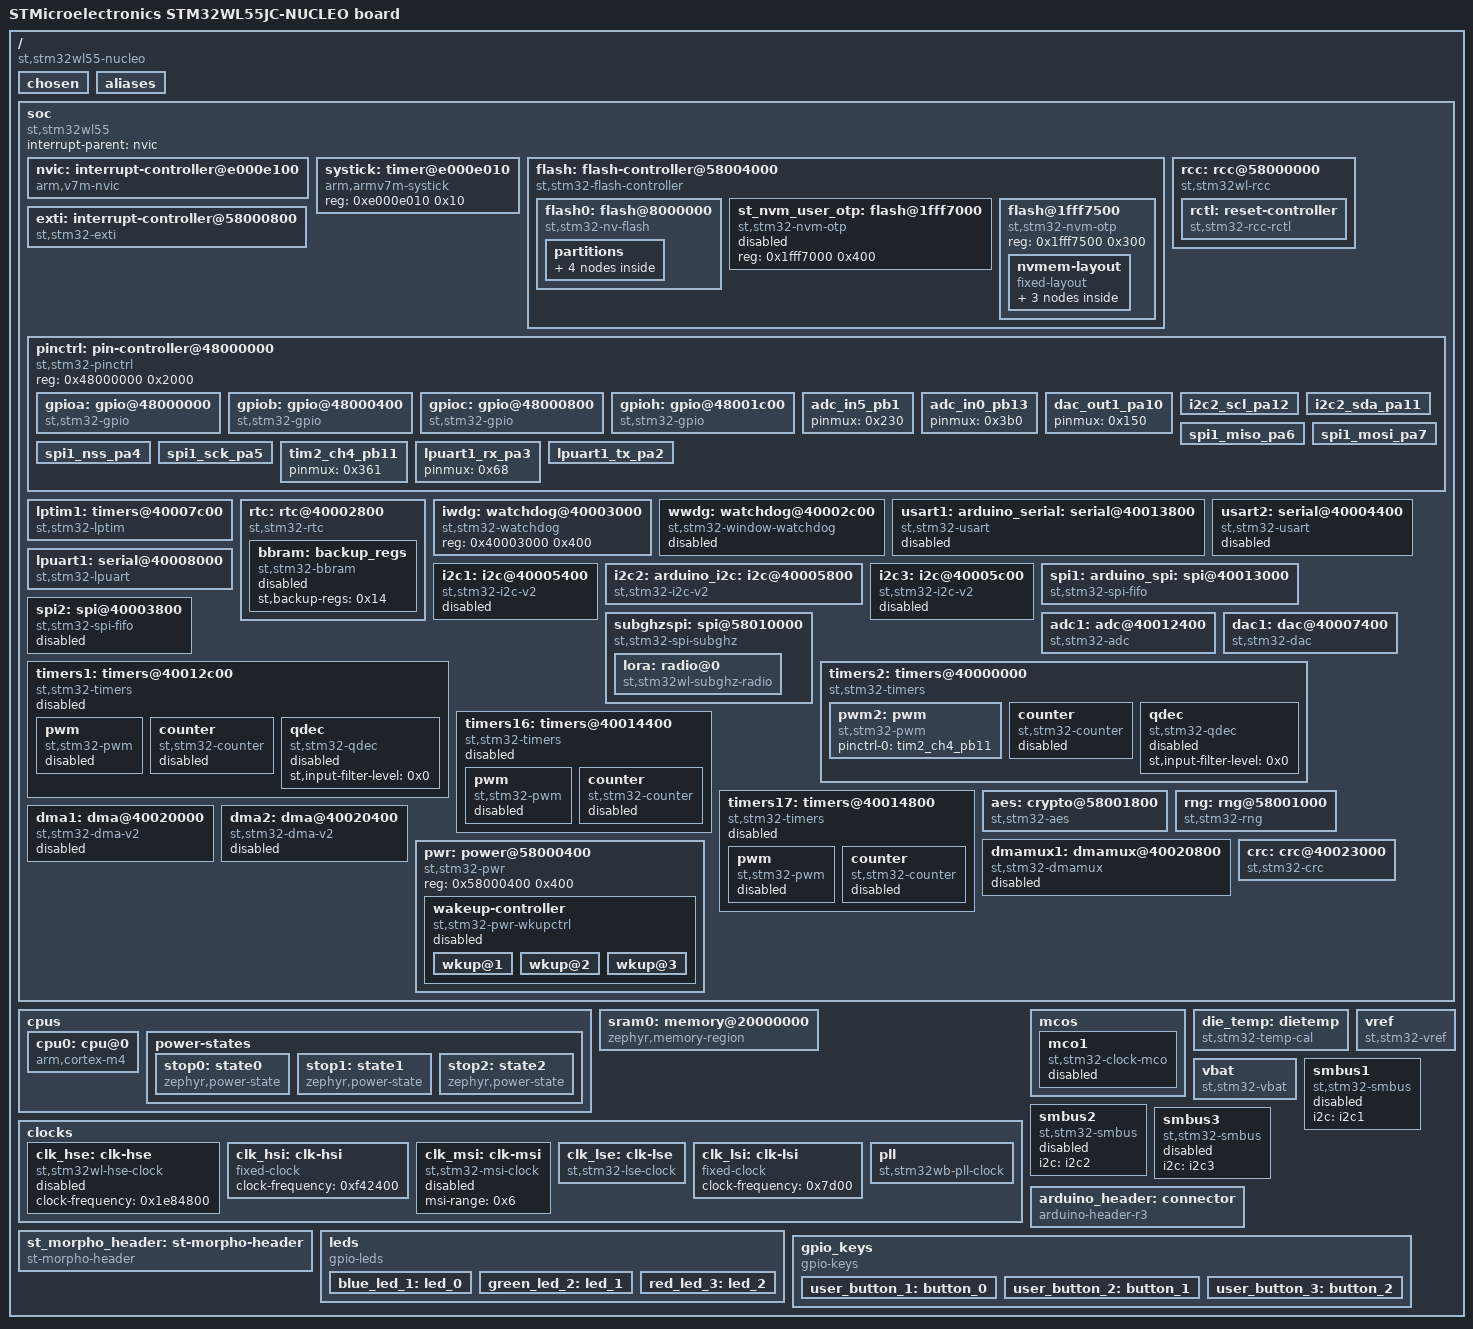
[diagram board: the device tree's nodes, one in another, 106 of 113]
/dts-v1/;

/* node '/' defined in zephyr\dts\common\skeleton.dtsi:9 */
/ {
	#address-cells = < 0x1 >;                              /* in zephyr\dts\common\skeleton.dtsi:10 */
	#size-cells = < 0x1 >;                                 /* in zephyr\dts\common\skeleton.dtsi:11 */
	model = "STMicroelectronics STM32WL55JC-NUCLEO board"; /* in zephyr\boards\st\nucleo_wl55jc\nucleo_wl55jc.dts:15 */
	compatible = "st,stm32wl55-nucleo";                    /* in zephyr\boards\st\nucleo_wl55jc\nucleo_wl55jc.dts:16 */

	/* node '/chosen' defined in zephyr\dts\common\skeleton.dtsi:13 */
	chosen {
		zephyr,crc = &crc;                        /* in zephyr\dts\arm\st\wl\stm32wl.dtsi:24 */
		zephyr,entropy = &rng;                    /* in zephyr\dts\arm\st\wl\stm32wl.dtsi:25 */
		zephyr,flash-controller = &flash;         /* in zephyr\dts\arm\st\wl\stm32wl.dtsi:26 */
		zephyr,console = &lpuart1;                /* in zephyr\boards\st\nucleo_wl55jc\nucleo_wl55jc.dts:19 */
		zephyr,shell-uart = &lpuart1;             /* in zephyr\boards\st\nucleo_wl55jc\nucleo_wl55jc.dts:20 */
		zephyr,sram = &sram0;                     /* in zephyr\boards\st\nucleo_wl55jc\nucleo_wl55jc.dts:21 */
		zephyr,flash = &flash0;                   /* in zephyr\boards\st\nucleo_wl55jc\nucleo_wl55jc.dts:22 */
		zephyr,code-partition = &slot0_partition; /* in zephyr\boards\st\nucleo_wl55jc\nucleo_wl55jc.dts:23 */
		zephyr,system-timer = &lptim1;            /* in zephyr\boards\st\nucleo_wl55jc\nucleo_wl55jc.dts:24 */
	};

	/* node '/aliases' defined in zephyr\dts\common\skeleton.dtsi:15 */
	aliases {
		rtc = &rtc;            /* in zephyr\boards\st\nucleo_wl55jc\nucleo_wl55jc.dts:70 */
		sw0 = &user_button_1;  /* in zephyr\boards\st\nucleo_wl55jc\nucleo_wl55jc.dts:71 */
		sw1 = &user_button_2;  /* in zephyr\boards\st\nucleo_wl55jc\nucleo_wl55jc.dts:72 */
		sw2 = &user_button_3;  /* in zephyr\boards\st\nucleo_wl55jc\nucleo_wl55jc.dts:73 */
		lora0 = &lora;         /* in zephyr\boards\st\nucleo_wl55jc\nucleo_wl55jc.dts:74 */
		watchdog0 = &iwdg;     /* in zephyr\boards\st\nucleo_wl55jc\nucleo_wl55jc.dts:75 */
		die-temp0 = &die_temp; /* in zephyr\boards\st\nucleo_wl55jc\nucleo_wl55jc.dts:76 */
		volt-sensor0 = &vref;  /* in zephyr\boards\st\nucleo_wl55jc\nucleo_wl55jc.dts:77 */
		volt-sensor1 = &vbat;  /* in zephyr\boards\st\nucleo_wl55jc\nucleo_wl55jc.dts:78 */
		led0 = &red_led_3;     /* in ..\brightnessm_iot\build\zephyr\boards\nucleo_wl55jc.overlay:7 */
	};

	/* node '/soc' defined in zephyr\dts\arm\armv7-m.dtsi:6 */
	soc {
		#address-cells = < 0x1 >;     /* in zephyr\dts\arm\armv7-m.dtsi:7 */
		#size-cells = < 0x1 >;        /* in zephyr\dts\arm\armv7-m.dtsi:8 */
		interrupt-parent = < &nvic >; /* in zephyr\dts\arm\armv7-m.dtsi:10 */
		ranges;                       /* in zephyr\dts\arm\armv7-m.dtsi:11 */
		compatible = "st,stm32wl55",
		             "st,stm32wl",
		             "simple-bus";    /* in zephyr\dts\arm\st\wl\stm32wl55.dtsi:11 */

		/* node '/soc/interrupt-controller@e000e100' defined in zephyr\dts\arm\armv7-m.dtsi:13 */
		nvic: interrupt-controller@e000e100 {
			#address-cells = < 0x1 >;            /* in zephyr\dts\arm\armv7-m.dtsi:14 */
			compatible = "arm,v7m-nvic";         /* in zephyr\dts\arm\armv7-m.dtsi:15 */
			reg = < 0xe000e100 0xc00 >;          /* in zephyr\dts\arm\armv7-m.dtsi:16 */
			interrupt-controller;                /* in zephyr\dts\arm\armv7-m.dtsi:17 */
			#interrupt-cells = < 0x2 >;          /* in zephyr\dts\arm\armv7-m.dtsi:18 */
			arm,num-irq-priority-bits = < 0x4 >; /* in zephyr\dts\arm\st\wl\stm32wl.dtsi:673 */
			phandle = < 0x1 >;                   /* in zephyr\dts\arm\armv7-m.dtsi:10 */
		};

		/* node '/soc/timer@e000e010' defined in zephyr\dts\arm\armv7-m.dtsi:21 */
		systick: timer@e000e010 {
			compatible = "arm,armv7m-systick"; /* in zephyr\dts\arm\armv7-m.dtsi:22 */
			reg = < 0xe000e010 0x10 >;         /* in zephyr\dts\arm\armv7-m.dtsi:23 */
		};

		/* node '/soc/flash-controller@58004000' defined in zephyr\dts\arm\st\wl\stm32wl.dtsi:123 */
		flash: flash-controller@58004000 {
			compatible = "st,stm32-flash-controller",
			             "st,stm32l4-flash-controller"; /* in zephyr\dts\arm\st\wl\stm32wl.dtsi:124 */
			reg = < 0x58004000 0x400 >;                 /* in zephyr\dts\arm\st\wl\stm32wl.dtsi:125 */
			interrupts = < 0x4 0x0 >;                   /* in zephyr\dts\arm\st\wl\stm32wl.dtsi:126 */
			#address-cells = < 0x1 >;                   /* in zephyr\dts\arm\st\wl\stm32wl.dtsi:128 */
			#size-cells = < 0x1 >;                      /* in zephyr\dts\arm\st\wl\stm32wl.dtsi:129 */
			ranges;                                     /* in zephyr\dts\arm\st\wl\stm32wl.dtsi:130 */

			/* node '/soc/flash-controller@58004000/flash@8000000' defined in zephyr\dts\arm\st\wl\stm32wl.dtsi:132 */
			flash0: flash@8000000 {
				compatible = "st,stm32-nv-flash",
				             "soc-nv-flash";        /* in zephyr\dts\arm\st\wl\stm32wl.dtsi:133 */
				#address-cells = < 0x1 >;           /* in zephyr\dts\arm\st\wl\stm32wl.dtsi:134 */
				#size-cells = < 0x1 >;              /* in zephyr\dts\arm\st\wl\stm32wl.dtsi:135 */
				write-block-size = < 0x8 >;         /* in zephyr\dts\arm\st\wl\stm32wl.dtsi:136 */
				erase-block-size = < 0x800 >;       /* in zephyr\dts\arm\st\wl\stm32wl.dtsi:137 */
				max-erase-time = < 0x19 >;          /* in zephyr\dts\arm\st\wl\stm32wl.dtsi:139 */
				reg = < 0x8000000 0x40000 >;        /* in zephyr\dts\arm\st\wl\stm32wl55Xc.dtsi:16 */
				ranges = < 0x0 0x8000000 0x40000 >; /* in zephyr\dts\arm\st\wl\stm32wl55Xc.dtsi:17 */

				/* node '/soc/flash-controller@58004000/flash@8000000/partitions' defined in zephyr\boards\st\nucleo_wl55jc\nucleo_wl55jc.dts:204 */
				partitions {
					#address-cells = < 0x1 >; /* in zephyr\boards\st\nucleo_wl55jc\nucleo_wl55jc.dts:205 */
					#size-cells = < 0x1 >;    /* in zephyr\boards\st\nucleo_wl55jc\nucleo_wl55jc.dts:206 */
					ranges;                   /* in zephyr\boards\st\nucleo_wl55jc\nucleo_wl55jc.dts:207 */

					/* node '/soc/flash-controller@58004000/flash@8000000/partitions/partition@0' defined in zephyr\boards\st\nucleo_wl55jc\nucleo_wl55jc.dts:209 */
					boot_partition: partition@0 {
						compatible = "zephyr,mapped-partition"; /* in zephyr\boards\st\nucleo_wl55jc\nucleo_wl55jc.dts:210 */
						label = "mcuboot";                      /* in zephyr\boards\st\nucleo_wl55jc\nucleo_wl55jc.dts:211 */
						reg = < 0x0 0xc000 >;                   /* in zephyr\boards\st\nucleo_wl55jc\nucleo_wl55jc.dts:212 */
						read-only;                              /* in zephyr\boards\st\nucleo_wl55jc\nucleo_wl55jc.dts:213 */
					};

					/* node '/soc/flash-controller@58004000/flash@8000000/partitions/partition@c000' defined in zephyr\boards\st\nucleo_wl55jc\nucleo_wl55jc.dts:216 */
					slot0_partition: partition@c000 {
						compatible = "zephyr,mapped-partition"; /* in zephyr\boards\st\nucleo_wl55jc\nucleo_wl55jc.dts:217 */
						label = "image-0";                      /* in zephyr\boards\st\nucleo_wl55jc\nucleo_wl55jc.dts:218 */
						reg = < 0xc000 0x18800 >;               /* in zephyr\boards\st\nucleo_wl55jc\nucleo_wl55jc.dts:219 */
					};

					/* node '/soc/flash-controller@58004000/flash@8000000/partitions/partition@24800' defined in zephyr\boards\st\nucleo_wl55jc\nucleo_wl55jc.dts:222 */
					slot1_partition: partition@24800 {
						compatible = "zephyr,mapped-partition"; /* in zephyr\boards\st\nucleo_wl55jc\nucleo_wl55jc.dts:223 */
						label = "image-1";                      /* in zephyr\boards\st\nucleo_wl55jc\nucleo_wl55jc.dts:224 */
						reg = < 0x24800 0x19000 >;              /* in zephyr\boards\st\nucleo_wl55jc\nucleo_wl55jc.dts:225 */
					};

					/* node '/soc/flash-controller@58004000/flash@8000000/partitions/partition@3d800' defined in zephyr\boards\st\nucleo_wl55jc\nucleo_wl55jc.dts:228 */
					storage_partition: partition@3d800 {
						compatible = "zephyr,mapped-partition"; /* in zephyr\boards\st\nucleo_wl55jc\nucleo_wl55jc.dts:229 */
						label = "storage";                      /* in zephyr\boards\st\nucleo_wl55jc\nucleo_wl55jc.dts:230 */
						reg = < 0x3d800 0x2800 >;               /* in zephyr\boards\st\nucleo_wl55jc\nucleo_wl55jc.dts:231 */
					};
				};
			};

			/* node '/soc/flash-controller@58004000/flash@1fff7000' defined in zephyr\dts\arm\st\wl\stm32wl.dtsi:142 */
			st_nvm_user_otp: flash@1fff7000 {
				compatible = "st,stm32-nvm-otp"; /* in zephyr\dts\arm\st\wl\stm32wl.dtsi:143 */
				reg = < 0x1fff7000 0x400 >;      /* in zephyr\dts\arm\st\wl\stm32wl.dtsi:144 */
				status = "disabled";             /* in zephyr\dts\arm\st\wl\stm32wl.dtsi:145 */
			};

			/* node '/soc/flash-controller@58004000/flash@1fff7500' defined in zephyr\dts\arm\st\wl\stm32wl.dtsi:149 */
			flash@1fff7500 {
				compatible = "st,stm32-nvm-otp"; /* in zephyr\dts\arm\st\wl\stm32wl.dtsi:150 */
				reg = < 0x1fff7500 0x300 >;      /* in zephyr\dts\arm\st\wl\stm32wl.dtsi:151 */

				/* node '/soc/flash-controller@58004000/flash@1fff7500/nvmem-layout' defined in zephyr\dts\arm\st\wl\stm32wl.dtsi:153 */
				nvmem-layout {
					compatible = "fixed-layout"; /* in zephyr\dts\arm\st\wl\stm32wl.dtsi:154 */
					#address-cells = < 0x1 >;    /* in zephyr\dts\arm\st\wl\stm32wl.dtsi:155 */
					#size-cells = < 0x1 >;       /* in zephyr\dts\arm\st\wl\stm32wl.dtsi:156 */

					/* node '/soc/flash-controller@58004000/flash@1fff7500/nvmem-layout/ts-cal1@a8' defined in zephyr\dts\arm\st\wl\stm32wl.dtsi:158 */
					ts_cal1_otp: ts-cal1@a8 {
						reg = < 0xa8 0x2 >;          /* in zephyr\dts\arm\st\wl\stm32wl.dtsi:159 */
						#nvmem-cell-cells = < 0x0 >; /* in zephyr\dts\arm\st\wl\stm32wl.dtsi:160 */
						read-only;                   /* in zephyr\dts\arm\st\wl\stm32wl.dtsi:161 */
						phandle = < 0x18 >;          /* in zephyr\dts\arm\st\wl\stm32wl.dtsi:623 */
					};

					/* node '/soc/flash-controller@58004000/flash@1fff7500/nvmem-layout/vrefint@aa' defined in zephyr\dts\arm\st\wl\stm32wl.dtsi:164 */
					vrefint_otp: vrefint@aa {
						reg = < 0xaa 0x2 >;          /* in zephyr\dts\arm\st\wl\stm32wl.dtsi:165 */
						#nvmem-cell-cells = < 0x0 >; /* in zephyr\dts\arm\st\wl\stm32wl.dtsi:166 */
						read-only;                   /* in zephyr\dts\arm\st\wl\stm32wl.dtsi:167 */
						phandle = < 0x1b >;          /* in zephyr\dts\arm\st\wl\stm32wl.dtsi:634 */
					};

					/* node '/soc/flash-controller@58004000/flash@1fff7500/nvmem-layout/ts-cal2@c8' defined in zephyr\dts\arm\st\wl\stm32wl.dtsi:170 */
					ts_cal2_otp: ts-cal2@c8 {
						reg = < 0xc8 0x2 >;          /* in zephyr\dts\arm\st\wl\stm32wl.dtsi:171 */
						#nvmem-cell-cells = < 0x0 >; /* in zephyr\dts\arm\st\wl\stm32wl.dtsi:172 */
						read-only;                   /* in zephyr\dts\arm\st\wl\stm32wl.dtsi:173 */
						phandle = < 0x19 >;          /* in zephyr\dts\arm\st\wl\stm32wl.dtsi:623 */
					};
				};
			};
		};

		/* node '/soc/rcc@58000000' defined in zephyr\dts\arm\st\wl\stm32wl.dtsi:179 */
		rcc: rcc@58000000 {
			compatible = "st,stm32wl-rcc";   /* in zephyr\dts\arm\st\wl\stm32wl.dtsi:180 */
			#clock-cells = < 0x2 >;          /* in zephyr\dts\arm\st\wl\stm32wl.dtsi:181 */
			reg = < 0x58000000 0x400 >;      /* in zephyr\dts\arm\st\wl\stm32wl.dtsi:182 */
			clocks = < &pll >;               /* in zephyr\boards\st\nucleo_wl55jc\nucleo_wl55jc.dts:111 */
			clock-frequency = < 0x2dc6c00 >; /* in zephyr\boards\st\nucleo_wl55jc\nucleo_wl55jc.dts:112 */
			cpu1-prescaler = < 0x1 >;        /* in zephyr\boards\st\nucleo_wl55jc\nucleo_wl55jc.dts:113 */
			cpu2-prescaler = < 0x1 >;        /* in zephyr\boards\st\nucleo_wl55jc\nucleo_wl55jc.dts:114 */
			ahb3-prescaler = < 0x1 >;        /* in zephyr\boards\st\nucleo_wl55jc\nucleo_wl55jc.dts:115 */
			apb1-prescaler = < 0x1 >;        /* in zephyr\boards\st\nucleo_wl55jc\nucleo_wl55jc.dts:116 */
			apb2-prescaler = < 0x1 >;        /* in zephyr\boards\st\nucleo_wl55jc\nucleo_wl55jc.dts:117 */
			phandle = < 0x3 >;               /* in zephyr\dts\arm\st\wl\stm32wl.dtsi:196 */

			/* node '/soc/rcc@58000000/reset-controller' defined in zephyr\dts\arm\st\wl\stm32wl.dtsi:184 */
			rctl: reset-controller {
				compatible = "st,stm32-rcc-rctl"; /* in zephyr\dts\arm\st\wl\stm32wl.dtsi:185 */
				#reset-cells = < 0x1 >;           /* in zephyr\dts\arm\st\wl\stm32wl.dtsi:186 */
				phandle = < 0x4 >;                /* in zephyr\dts\arm\st\wl\stm32wl.dtsi:249 */
			};
		};

		/* node '/soc/interrupt-controller@58000800' defined in zephyr\dts\arm\st\wl\stm32wl.dtsi:190 */
		exti: interrupt-controller@58000800 {
			compatible = "st,stm32-exti";  /* in zephyr\dts\arm\st\wl\stm32wl.dtsi:191 */
			interrupt-controller;          /* in zephyr\dts\arm\st\wl\stm32wl.dtsi:192 */
			#interrupt-cells = < 0x1 >;    /* in zephyr\dts\arm\st\wl\stm32wl.dtsi:193 */
			#address-cells = < 0x0 >;      /* in zephyr\dts\arm\st\wl\stm32wl.dtsi:194 */
			reg = < 0x58000800 0x400 >;    /* in zephyr\dts\arm\st\wl\stm32wl.dtsi:195 */
			clocks = < &rcc 0x54 0x100 >;  /* in zephyr\dts\arm\st\wl\stm32wl.dtsi:196 */
			num-lines = < 0x40 >;          /* in zephyr\dts\arm\st\wl\stm32wl.dtsi:197 */
			interrupts = < 0x6 0x0 >,
			             < 0x7 0x0 >,
			             < 0x8 0x0 >,
			             < 0x9 0x0 >,
			             < 0xa 0x0 >,
			             < 0x16 0x0 >,
			             < 0x29 0x0 >;     /* in zephyr\dts\arm\st\wl\stm32wl.dtsi:198 */
			interrupt-names = "line0",
			                  "line1",
			                  "line2",
			                  "line3",
			                  "line4",
			                  "line5-9",
			                  "line10-15"; /* in zephyr\dts\arm\st\wl\stm32wl.dtsi:200 */
			line-ranges = < 0x0 0x1 >,
			              < 0x1 0x1 >,
			              < 0x2 0x1 >,
			              < 0x3 0x1 >,
			              < 0x4 0x1 >,
			              < 0x5 0x5 >,
			              < 0xa 0x6 >;     /* in zephyr\dts\arm\st\wl\stm32wl.dtsi:202 */
		};

		/* node '/soc/pin-controller@48000000' defined in zephyr\dts\arm\st\wl\stm32wl.dtsi:206 */
		pinctrl: pin-controller@48000000 {
			compatible = "st,stm32-pinctrl"; /* in zephyr\dts\arm\st\wl\stm32wl.dtsi:207 */
			#address-cells = < 0x1 >;        /* in zephyr\dts\arm\st\wl\stm32wl.dtsi:208 */
			#size-cells = < 0x1 >;           /* in zephyr\dts\arm\st\wl\stm32wl.dtsi:209 */
			reg = < 0x48000000 0x2000 >;     /* in zephyr\dts\arm\st\wl\stm32wl.dtsi:210 */
			ranges;                          /* in zephyr\dts\arm\st\wl\stm32wl.dtsi:211 */

			/* node '/soc/pin-controller@48000000/gpio@48000000' defined in zephyr\dts\arm\st\wl\stm32wl.dtsi:213 */
			gpioa: gpio@48000000 {
				compatible = "st,stm32-gpio"; /* in zephyr\dts\arm\st\wl\stm32wl.dtsi:214 */
				gpio-controller;              /* in zephyr\dts\arm\st\wl\stm32wl.dtsi:215 */
				#gpio-cells = < 0x2 >;        /* in zephyr\dts\arm\st\wl\stm32wl.dtsi:216 */
				reg = < 0x48000000 0x400 >;   /* in zephyr\dts\arm\st\wl\stm32wl.dtsi:217 */
				clocks = < &rcc 0x4c 0x1 >;   /* in zephyr\dts\arm\st\wl\stm32wl.dtsi:218 */
				phandle = < 0x9 >;            /* in zephyr\boards\st\nucleo_wl55jc\nucleo_wl55jc.dts:130 */
			};

			/* node '/soc/pin-controller@48000000/gpio@48000400' defined in zephyr\dts\arm\st\wl\stm32wl.dtsi:221 */
			gpiob: gpio@48000400 {
				compatible = "st,stm32-gpio"; /* in zephyr\dts\arm\st\wl\stm32wl.dtsi:222 */
				gpio-controller;              /* in zephyr\dts\arm\st\wl\stm32wl.dtsi:223 */
				#gpio-cells = < 0x2 >;        /* in zephyr\dts\arm\st\wl\stm32wl.dtsi:224 */
				reg = < 0x48000400 0x400 >;   /* in zephyr\dts\arm\st\wl\stm32wl.dtsi:225 */
				clocks = < &rcc 0x4c 0x2 >;   /* in zephyr\dts\arm\st\wl\stm32wl.dtsi:226 */
				phandle = < 0x13 >;           /* in zephyr\dts\arm\st\wl\stm32wl.dtsi:607 */
			};

			/* node '/soc/pin-controller@48000000/gpio@48000800' defined in zephyr\dts\arm\st\wl\stm32wl.dtsi:229 */
			gpioc: gpio@48000800 {
				compatible = "st,stm32-gpio"; /* in zephyr\dts\arm\st\wl\stm32wl.dtsi:230 */
				gpio-controller;              /* in zephyr\dts\arm\st\wl\stm32wl.dtsi:231 */
				#gpio-cells = < 0x2 >;        /* in zephyr\dts\arm\st\wl\stm32wl.dtsi:232 */
				reg = < 0x48000800 0x400 >;   /* in zephyr\dts\arm\st\wl\stm32wl.dtsi:233 */
				clocks = < &rcc 0x4c 0x4 >;   /* in zephyr\dts\arm\st\wl\stm32wl.dtsi:234 */
				phandle = < 0xe >;            /* in zephyr\boards\st\nucleo_wl55jc\nucleo_wl55jc.dts:188 */
			};

			/* node '/soc/pin-controller@48000000/gpio@48001c00' defined in zephyr\dts\arm\st\wl\stm32wl.dtsi:237 */
			gpioh: gpio@48001c00 {
				compatible = "st,stm32-gpio"; /* in zephyr\dts\arm\st\wl\stm32wl.dtsi:238 */
				gpio-controller;              /* in zephyr\dts\arm\st\wl\stm32wl.dtsi:239 */
				#gpio-cells = < 0x2 >;        /* in zephyr\dts\arm\st\wl\stm32wl.dtsi:240 */
				reg = < 0x48001c00 0x400 >;   /* in zephyr\dts\arm\st\wl\stm32wl.dtsi:241 */
				clocks = < &rcc 0x4c 0x80 >;  /* in zephyr\dts\arm\st\wl\stm32wl.dtsi:242 */
				phandle = < 0x1f >;           /* in zephyr\boards\st\nucleo_wl55jc\st_morpho_connector.dtsi:15 */
			};

			/* node '/soc/pin-controller@48000000/adc_in5_pb1' defined in modules\hal\stm32\dts\st\wl\stm32wl55jcix-pinctrl.dtsi:35 */
			adc_in5_pb1: adc_in5_pb1 {
				pinmux = < 0x230 >; /* in modules\hal\stm32\dts\st\wl\stm32wl55jcix-pinctrl.dtsi:36 */
				phandle = < 0xf >;  /* in zephyr\boards\st\nucleo_wl55jc\nucleo_wl55jc.dts:160 */
			};

			/* node '/soc/pin-controller@48000000/adc_in0_pb13' defined in modules\hal\stm32\dts\st\wl\stm32wl55jcix-pinctrl.dtsi:51 */
			adc_in0_pb13: adc_in0_pb13 {
				pinmux = < 0x3b0 >; /* in modules\hal\stm32\dts\st\wl\stm32wl55jcix-pinctrl.dtsi:52 */
				phandle = < 0x10 >; /* in zephyr\boards\st\nucleo_wl55jc\nucleo_wl55jc.dts:160 */
			};

			/* node '/soc/pin-controller@48000000/dac_out1_pa10' defined in modules\hal\stm32\dts\st\wl\stm32wl55jcix-pinctrl.dtsi:315 */
			dac_out1_pa10: dac_out1_pa10 {
				pinmux = < 0x150 >; /* in modules\hal\stm32\dts\st\wl\stm32wl55jcix-pinctrl.dtsi:316 */
				phandle = < 0x11 >; /* in zephyr\boards\st\nucleo_wl55jc\nucleo_wl55jc.dts:144 */
			};

			/* node '/soc/pin-controller@48000000/i2c2_scl_pa12' defined in modules\hal\stm32\dts\st\wl\stm32wl55jcix-pinctrl.dtsi:338 */
			i2c2_scl_pa12: i2c2_scl_pa12 {
				pinmux = < 0x184 >; /* in modules\hal\stm32\dts\st\wl\stm32wl55jcix-pinctrl.dtsi:339 */
				bias-pull-up;       /* in modules\hal\stm32\dts\st\wl\stm32wl55jcix-pinctrl.dtsi:340 */
				drive-open-drain;   /* in modules\hal\stm32\dts\st\wl\stm32wl55jcix-pinctrl.dtsi:341 */
				phandle = < 0x7 >;  /* in zephyr\boards\st\nucleo_wl55jc\nucleo_wl55jc.dts:128 */
			};

			/* node '/soc/pin-controller@48000000/i2c2_sda_pa11' defined in modules\hal\stm32\dts\st\wl\stm32wl55jcix-pinctrl.dtsi:393 */
			i2c2_sda_pa11: i2c2_sda_pa11 {
				pinmux = < 0x164 >; /* in modules\hal\stm32\dts\st\wl\stm32wl55jcix-pinctrl.dtsi:394 */
				bias-pull-up;       /* in modules\hal\stm32\dts\st\wl\stm32wl55jcix-pinctrl.dtsi:395 */
				drive-open-drain;   /* in modules\hal\stm32\dts\st\wl\stm32wl55jcix-pinctrl.dtsi:396 */
				phandle = < 0x8 >;  /* in zephyr\boards\st\nucleo_wl55jc\nucleo_wl55jc.dts:128 */
			};

			/* node '/soc/pin-controller@48000000/spi1_miso_pa6' defined in modules\hal\stm32\dts\st\wl\stm32wl55jcix-pinctrl.dtsi:642 */
			spi1_miso_pa6: spi1_miso_pa6 {
				pinmux = < 0xc5 >;             /* in modules\hal\stm32\dts\st\wl\stm32wl55jcix-pinctrl.dtsi:643 */
				bias-pull-down;                /* in modules\hal\stm32\dts\st\wl\stm32wl55jcix-pinctrl.dtsi:644 */
				slew-rate = "very-high-speed"; /* in modules\hal\stm32\dts\st\wl\stm32wl55jcix-pinctrl.dtsi:645 */
				phandle = < 0xc >;             /* in zephyr\boards\st\nucleo_wl55jc\nucleo_wl55jc.dts:137 */
			};

			/* node '/soc/pin-controller@48000000/spi1_mosi_pa7' defined in modules\hal\stm32\dts\st\wl\stm32wl55jcix-pinctrl.dtsi:679 */
			spi1_mosi_pa7: spi1_mosi_pa7 {
				pinmux = < 0xe5 >;             /* in modules\hal\stm32\dts\st\wl\stm32wl55jcix-pinctrl.dtsi:680 */
				bias-pull-down;                /* in modules\hal\stm32\dts\st\wl\stm32wl55jcix-pinctrl.dtsi:681 */
				slew-rate = "very-high-speed"; /* in modules\hal\stm32\dts\st\wl\stm32wl55jcix-pinctrl.dtsi:682 */
				phandle = < 0xd >;             /* in zephyr\boards\st\nucleo_wl55jc\nucleo_wl55jc.dts:137 */
			};

			/* node '/soc/pin-controller@48000000/spi1_nss_pa4' defined in modules\hal\stm32\dts\st\wl\stm32wl55jcix-pinctrl.dtsi:722 */
			spi1_nss_pa4: spi1_nss_pa4 {
				pinmux = < 0x85 >;             /* in modules\hal\stm32\dts\st\wl\stm32wl55jcix-pinctrl.dtsi:723 */
				bias-pull-up;                  /* in modules\hal\stm32\dts\st\wl\stm32wl55jcix-pinctrl.dtsi:724 */
				slew-rate = "very-high-speed"; /* in modules\hal\stm32\dts\st\wl\stm32wl55jcix-pinctrl.dtsi:725 */
				phandle = < 0xa >;             /* in zephyr\boards\st\nucleo_wl55jc\nucleo_wl55jc.dts:137 */
			};

			/* node '/soc/pin-controller@48000000/spi1_sck_pa5' defined in modules\hal\stm32\dts\st\wl\stm32wl55jcix-pinctrl.dtsi:765 */
			spi1_sck_pa5: spi1_sck_pa5 {
				pinmux = < 0xa5 >;             /* in modules\hal\stm32\dts\st\wl\stm32wl55jcix-pinctrl.dtsi:766 */
				bias-pull-down;                /* in modules\hal\stm32\dts\st\wl\stm32wl55jcix-pinctrl.dtsi:767 */
				slew-rate = "very-high-speed"; /* in modules\hal\stm32\dts\st\wl\stm32wl55jcix-pinctrl.dtsi:768 */
				phandle = < 0xb >;             /* in zephyr\boards\st\nucleo_wl55jc\nucleo_wl55jc.dts:137 */
			};

			/* node '/soc/pin-controller@48000000/tim2_ch4_pb11' defined in modules\hal\stm32\dts\st\wl\stm32wl55jcix-pinctrl.dtsi:903 */
			tim2_ch4_pb11: tim2_ch4_pb11 {
				pinmux = < 0x361 >; /* in modules\hal\stm32\dts\st\wl\stm32wl55jcix-pinctrl.dtsi:904 */
				phandle = < 0x12 >; /* in zephyr\boards\st\nucleo_wl55jc\nucleo_wl55jc.dts:154 */
			};

			/* node '/soc/pin-controller@48000000/lpuart1_rx_pa3' defined in modules\hal\stm32\dts\st\wl\stm32wl55jcix-pinctrl.dtsi:1010 */
			lpuart1_rx_pa3: lpuart1_rx_pa3 {
				pinmux = < 0x68 >; /* in modules\hal\stm32\dts\st\wl\stm32wl55jcix-pinctrl.dtsi:1011 */
				phandle = < 0x6 >; /* in zephyr\boards\st\nucleo_wl55jc\nucleo_wl55jc.dts:121 */
			};

			/* node '/soc/pin-controller@48000000/lpuart1_tx_pa2' defined in modules\hal\stm32\dts\st\wl\stm32wl55jcix-pinctrl.dtsi:1035 */
			lpuart1_tx_pa2: lpuart1_tx_pa2 {
				pinmux = < 0x48 >; /* in modules\hal\stm32\dts\st\wl\stm32wl55jcix-pinctrl.dtsi:1036 */
				bias-pull-up;      /* in modules\hal\stm32\dts\st\wl\stm32wl55jcix-pinctrl.dtsi:1037 */
				phandle = < 0x5 >; /* in zephyr\boards\st\nucleo_wl55jc\nucleo_wl55jc.dts:121 */
			};
		};

		/* node '/soc/timers@40007c00' defined in zephyr\dts\arm\st\wl\stm32wl.dtsi:246 */
		lptim1: timers@40007c00 {
			compatible = "st,stm32-lptim";     /* in zephyr\dts\arm\st\wl\stm32wl.dtsi:247 */
			resets = < &rctl 0x71f >;          /* in zephyr\dts\arm\st\wl\stm32wl.dtsi:249 */
			#address-cells = < 0x1 >;          /* in zephyr\dts\arm\st\wl\stm32wl.dtsi:250 */
			#size-cells = < 0x0 >;             /* in zephyr\dts\arm\st\wl\stm32wl.dtsi:251 */
			reg = < 0x40007c00 0x400 >;        /* in zephyr\dts\arm\st\wl\stm32wl.dtsi:252 */
			interrupts = < 0x27 0x0 >;         /* in zephyr\dts\arm\st\wl\stm32wl.dtsi:253 */
			interrupt-names = "wakeup";        /* in zephyr\dts\arm\st\wl\stm32wl.dtsi:254 */
			clocks = < &rcc 0x58 0x80000000 >,
			         < &rcc 0x3 0x1320088 >;   /* in zephyr\boards\st\nucleo_wl55jc\nucleo_wl55jc.dts:87 */
			status = "okay";                   /* in zephyr\boards\st\nucleo_wl55jc\nucleo_wl55jc.dts:89 */
		};

		/* node '/soc/rtc@40002800' defined in zephyr\dts\arm\st\wl\stm32wl.dtsi:258 */
		rtc: rtc@40002800 {
			compatible = "st,stm32-rtc";     /* in zephyr\dts\arm\st\wl\stm32wl.dtsi:259 */
			reg = < 0x40002800 0x400 >;      /* in zephyr\dts\arm\st\wl\stm32wl.dtsi:260 */
			interrupts = < 0x2a 0x0 >;       /* in zephyr\dts\arm\st\wl\stm32wl.dtsi:261 */
			prescaler = < 0x8000 >;          /* in zephyr\dts\arm\st\wl\stm32wl.dtsi:263 */
			alarms-count = < 0x2 >;          /* in zephyr\dts\arm\st\wl\stm32wl.dtsi:264 */
			alrm-exti-line = < 0x11 >;       /* in zephyr\dts\arm\st\wl\stm32wl.dtsi:265 */
			clocks = < &rcc 0x58 0x400 >,
			         < &rcc 0x2 0x1280090 >; /* in zephyr\boards\st\nucleo_wl55jc\nucleo_wl55jc.dts:237 */
			status = "okay";                 /* in zephyr\boards\st\nucleo_wl55jc\nucleo_wl55jc.dts:239 */

			/* node '/soc/rtc@40002800/backup_regs' defined in zephyr\dts\arm\st\wl\stm32wl.dtsi:274 */
			bbram: backup_regs {
				compatible = "st,stm32-bbram"; /* in zephyr\dts\arm\st\wl\stm32wl.dtsi:275 */
				st,backup-regs = < 0x14 >;     /* in zephyr\dts\arm\st\wl\stm32wl.dtsi:276 */
				status = "disabled";           /* in zephyr\dts\arm\st\wl\stm32wl.dtsi:277 */
			};
		};

		/* node '/soc/watchdog@40003000' defined in zephyr\dts\arm\st\wl\stm32wl.dtsi:281 */
		iwdg: watchdog@40003000 {
			compatible = "st,stm32-watchdog"; /* in zephyr\dts\arm\st\wl\stm32wl.dtsi:282 */
			reg = < 0x40003000 0x400 >;       /* in zephyr\dts\arm\st\wl\stm32wl.dtsi:283 */
			status = "okay";                  /* in zephyr\boards\st\nucleo_wl55jc\nucleo_wl55jc.dts:180 */
		};

		/* node '/soc/watchdog@40002c00' defined in zephyr\dts\arm\st\wl\stm32wl.dtsi:287 */
		wwdg: watchdog@40002c00 {
			compatible = "st,stm32-window-watchdog"; /* in zephyr\dts\arm\st\wl\stm32wl.dtsi:288 */
			reg = < 0x40002c00 0x400 >;              /* in zephyr\dts\arm\st\wl\stm32wl.dtsi:289 */
			clocks = < &rcc 0x58 0x800 >;            /* in zephyr\dts\arm\st\wl\stm32wl.dtsi:290 */
			interrupts = < 0x0 0x0 >;                /* in zephyr\dts\arm\st\wl\stm32wl.dtsi:291 */
			status = "disabled";                     /* in zephyr\dts\arm\st\wl\stm32wl.dtsi:292 */
		};

		/* node '/soc/serial@40013800' defined in zephyr\dts\arm\st\wl\stm32wl.dtsi:295 */
		usart1: arduino_serial: serial@40013800 {
			compatible = "st,stm32-usart",
			             "st,stm32-uart";  /* in zephyr\dts\arm\st\wl\stm32wl.dtsi:296 */
			reg = < 0x40013800 0x400 >;    /* in zephyr\dts\arm\st\wl\stm32wl.dtsi:297 */
			clocks = < &rcc 0x60 0x4000 >; /* in zephyr\dts\arm\st\wl\stm32wl.dtsi:298 */
			resets = < &rctl 0x80e >;      /* in zephyr\dts\arm\st\wl\stm32wl.dtsi:299 */
			interrupts = < 0x24 0x0 >;     /* in zephyr\dts\arm\st\wl\stm32wl.dtsi:300 */
			status = "disabled";           /* in zephyr\dts\arm\st\wl\stm32wl.dtsi:301 */
		};

		/* node '/soc/serial@40004400' defined in zephyr\dts\arm\st\wl\stm32wl.dtsi:304 */
		usart2: serial@40004400 {
			compatible = "st,stm32-usart",
			             "st,stm32-uart";   /* in zephyr\dts\arm\st\wl\stm32wl.dtsi:305 */
			reg = < 0x40004400 0x400 >;     /* in zephyr\dts\arm\st\wl\stm32wl.dtsi:306 */
			clocks = < &rcc 0x58 0x20000 >; /* in zephyr\dts\arm\st\wl\stm32wl.dtsi:307 */
			resets = < &rctl 0x711 >;       /* in zephyr\dts\arm\st\wl\stm32wl.dtsi:308 */
			interrupts = < 0x25 0x0 >;      /* in zephyr\dts\arm\st\wl\stm32wl.dtsi:309 */
			status = "disabled";            /* in zephyr\dts\arm\st\wl\stm32wl.dtsi:310 */
		};

		/* node '/soc/serial@40008000' defined in zephyr\dts\arm\st\wl\stm32wl.dtsi:313 */
		lpuart1: serial@40008000 {
			compatible = "st,stm32-lpuart",
			             "st,stm32-uart";                    /* in zephyr\dts\arm\st\wl\stm32wl.dtsi:314 */
			reg = < 0x40008000 0x400 >;                      /* in zephyr\dts\arm\st\wl\stm32wl.dtsi:315 */
			clocks = < &rcc 0x5c 0x1 >;                      /* in zephyr\dts\arm\st\wl\stm32wl.dtsi:316 */
			resets = < &rctl 0x780 >;                        /* in zephyr\dts\arm\st\wl\stm32wl.dtsi:317 */
			interrupts = < 0x26 0x0 >;                       /* in zephyr\dts\arm\st\wl\stm32wl.dtsi:318 */
			wakeup-line = < 0x1c >;                          /* in zephyr\dts\arm\st\wl\stm32wl.dtsi:319 */
			pinctrl-0 = < &lpuart1_tx_pa2 &lpuart1_rx_pa3 >; /* in zephyr\boards\st\nucleo_wl55jc\nucleo_wl55jc.dts:121 */
			pinctrl-names = "default";                       /* in zephyr\boards\st\nucleo_wl55jc\nucleo_wl55jc.dts:122 */
			current-speed = < 0x1c200 >;                     /* in zephyr\boards\st\nucleo_wl55jc\nucleo_wl55jc.dts:123 */
			status = "okay";                                 /* in zephyr\boards\st\nucleo_wl55jc\nucleo_wl55jc.dts:124 */
		};

		/* node '/soc/i2c@40005400' defined in zephyr\dts\arm\st\wl\stm32wl.dtsi:323 */
		i2c1: i2c@40005400 {
			compatible = "st,stm32-i2c-v2";  /* in zephyr\dts\arm\st\wl\stm32wl.dtsi:324 */
			clock-frequency = < 0x186a0 >;   /* in zephyr\dts\arm\st\wl\stm32wl.dtsi:325 */
			#address-cells = < 0x1 >;        /* in zephyr\dts\arm\st\wl\stm32wl.dtsi:326 */
			#size-cells = < 0x0 >;           /* in zephyr\dts\arm\st\wl\stm32wl.dtsi:327 */
			reg = < 0x40005400 0x400 >;      /* in zephyr\dts\arm\st\wl\stm32wl.dtsi:328 */
			clocks = < &rcc 0x58 0x200000 >; /* in zephyr\dts\arm\st\wl\stm32wl.dtsi:329 */
			interrupts = < 0x1e 0x0 >,
			             < 0x1f 0x0 >;       /* in zephyr\dts\arm\st\wl\stm32wl.dtsi:330 */
			interrupt-names = "event",
			                  "error";       /* in zephyr\dts\arm\st\wl\stm32wl.dtsi:331 */
			status = "disabled";             /* in zephyr\dts\arm\st\wl\stm32wl.dtsi:332 */
			phandle = < 0x1c >;              /* in zephyr\dts\arm\st\wl\stm32wl.dtsi:651 */
		};

		/* node '/soc/i2c@40005800' defined in zephyr\dts\arm\st\wl\stm32wl.dtsi:335 */
		i2c2: arduino_i2c: i2c@40005800 {
			compatible = "st,stm32-i2c-v2";                /* in zephyr\dts\arm\st\wl\stm32wl.dtsi:336 */
			#address-cells = < 0x1 >;                      /* in zephyr\dts\arm\st\wl\stm32wl.dtsi:338 */
			#size-cells = < 0x0 >;                         /* in zephyr\dts\arm\st\wl\stm32wl.dtsi:339 */
			reg = < 0x40005800 0x400 >;                    /* in zephyr\dts\arm\st\wl\stm32wl.dtsi:340 */
			clocks = < &rcc 0x58 0x400000 >;               /* in zephyr\dts\arm\st\wl\stm32wl.dtsi:341 */
			interrupts = < 0x20 0x0 >,
			             < 0x21 0x0 >;                     /* in zephyr\dts\arm\st\wl\stm32wl.dtsi:342 */
			interrupt-names = "event",
			                  "error";                     /* in zephyr\dts\arm\st\wl\stm32wl.dtsi:343 */
			pinctrl-0 = < &i2c2_scl_pa12 &i2c2_sda_pa11 >; /* in zephyr\boards\st\nucleo_wl55jc\nucleo_wl55jc.dts:128 */
			pinctrl-names = "default";                     /* in zephyr\boards\st\nucleo_wl55jc\nucleo_wl55jc.dts:129 */
			scl-gpios = < &gpioa 0xc 0x0 >;                /* in zephyr\boards\st\nucleo_wl55jc\nucleo_wl55jc.dts:130 */
			sda-gpios = < &gpioa 0xb 0x0 >;                /* in zephyr\boards\st\nucleo_wl55jc\nucleo_wl55jc.dts:131 */
			status = "okay";                               /* in zephyr\boards\st\nucleo_wl55jc\nucleo_wl55jc.dts:132 */
			clock-frequency = < 0x61a80 >;                 /* in zephyr\boards\st\nucleo_wl55jc\nucleo_wl55jc.dts:133 */
			phandle = < 0x1d >;                            /* in zephyr\dts\arm\st\wl\stm32wl.dtsi:659 */
		};

		/* node '/soc/i2c@40005c00' defined in zephyr\dts\arm\st\wl\stm32wl.dtsi:347 */
		i2c3: i2c@40005c00 {
			compatible = "st,stm32-i2c-v2";  /* in zephyr\dts\arm\st\wl\stm32wl.dtsi:348 */
			clock-frequency = < 0x186a0 >;   /* in zephyr\dts\arm\st\wl\stm32wl.dtsi:349 */
			#address-cells = < 0x1 >;        /* in zephyr\dts\arm\st\wl\stm32wl.dtsi:350 */
			#size-cells = < 0x0 >;           /* in zephyr\dts\arm\st\wl\stm32wl.dtsi:351 */
			reg = < 0x40005c00 0x400 >;      /* in zephyr\dts\arm\st\wl\stm32wl.dtsi:352 */
			clocks = < &rcc 0x58 0x800000 >; /* in zephyr\dts\arm\st\wl\stm32wl.dtsi:353 */
			interrupts = < 0x30 0x0 >,
			             < 0x31 0x0 >;       /* in zephyr\dts\arm\st\wl\stm32wl.dtsi:354 */
			interrupt-names = "event",
			                  "error";       /* in zephyr\dts\arm\st\wl\stm32wl.dtsi:355 */
			status = "disabled";             /* in zephyr\dts\arm\st\wl\stm32wl.dtsi:356 */
			phandle = < 0x1e >;              /* in zephyr\dts\arm\st\wl\stm32wl.dtsi:667 */
		};

		/* node '/soc/spi@40013000' defined in zephyr\dts\arm\st\wl\stm32wl.dtsi:359 */
		spi1: arduino_spi: spi@40013000 {
			compatible = "st,stm32-spi-fifo",
			             "st,stm32-spi";                                               /* in zephyr\dts\arm\st\wl\stm32wl.dtsi:360 */
			#address-cells = < 0x1 >;                                                  /* in zephyr\dts\arm\st\wl\stm32wl.dtsi:361 */
			#size-cells = < 0x0 >;                                                     /* in zephyr\dts\arm\st\wl\stm32wl.dtsi:362 */
			reg = < 0x40013000 0x400 >;                                                /* in zephyr\dts\arm\st\wl\stm32wl.dtsi:363 */
			interrupts = < 0x22 0x0 >;                                                 /* in zephyr\dts\arm\st\wl\stm32wl.dtsi:364 */
			clocks = < &rcc 0x60 0x1000 >;                                             /* in zephyr\dts\arm\st\wl\stm32wl.dtsi:365 */
			st,spi-data-width = "full-4-to-16-bit";                                    /* in zephyr\dts\arm\st\wl\stm32wl.dtsi:366 */
			pinctrl-0 = < &spi1_nss_pa4 &spi1_sck_pa5 &spi1_miso_pa6 &spi1_mosi_pa7 >; /* in zephyr\boards\st\nucleo_wl55jc\nucleo_wl55jc.dts:137 */
			pinctrl-names = "default";                                                 /* in zephyr\boards\st\nucleo_wl55jc\nucleo_wl55jc.dts:139 */
			status = "okay";                                                           /* in zephyr\boards\st\nucleo_wl55jc\nucleo_wl55jc.dts:140 */
		};

		/* node '/soc/spi@40003800' defined in zephyr\dts\arm\st\wl\stm32wl.dtsi:370 */
		spi2: spi@40003800 {
			compatible = "st,stm32-spi-fifo",
			             "st,stm32-spi";            /* in zephyr\dts\arm\st\wl\stm32wl.dtsi:371 */
			#address-cells = < 0x1 >;               /* in zephyr\dts\arm\st\wl\stm32wl.dtsi:372 */
			#size-cells = < 0x0 >;                  /* in zephyr\dts\arm\st\wl\stm32wl.dtsi:373 */
			reg = < 0x40003800 0x400 >;             /* in zephyr\dts\arm\st\wl\stm32wl.dtsi:374 */
			interrupts = < 0x23 0x0 >;              /* in zephyr\dts\arm\st\wl\stm32wl.dtsi:375 */
			clocks = < &rcc 0x58 0x4000 >;          /* in zephyr\dts\arm\st\wl\stm32wl.dtsi:376 */
			st,spi-data-width = "full-4-to-16-bit"; /* in zephyr\dts\arm\st\wl\stm32wl.dtsi:377 */
			status = "disabled";                    /* in zephyr\dts\arm\st\wl\stm32wl.dtsi:378 */
		};

		/* node '/soc/spi@58010000' defined in zephyr\dts\arm\st\wl\stm32wl.dtsi:381 */
		subghzspi: spi@58010000 {
			compatible = "st,stm32-spi-subghz",
			             "st,stm32-spi-fifo",
			             "st,stm32-spi";            /* in zephyr\dts\arm\st\wl\stm32wl.dtsi:382 */
			#address-cells = < 0x1 >;               /* in zephyr\dts\arm\st\wl\stm32wl.dtsi:383 */
			#size-cells = < 0x0 >;                  /* in zephyr\dts\arm\st\wl\stm32wl.dtsi:384 */
			reg = < 0x58010000 0x400 >;             /* in zephyr\dts\arm\st\wl\stm32wl.dtsi:385 */
			interrupts = < 0x2c 0x0 >;              /* in zephyr\dts\arm\st\wl\stm32wl.dtsi:386 */
			clocks = < &rcc 0x64 0x1 >;             /* in zephyr\dts\arm\st\wl\stm32wl.dtsi:387 */
			st,spi-data-width = "full-4-to-16-bit"; /* in zephyr\dts\arm\st\wl\stm32wl.dtsi:388 */
			status = "okay";                        /* in zephyr\boards\st\nucleo_wl55jc\nucleo_wl55jc.dts:184 */

			/* node '/soc/spi@58010000/radio@0' defined in zephyr\dts\arm\st\wl\stm32wl.dtsi:391 */
			lora: radio@0 {
				compatible = "st,stm32wl-subghz-radio"; /* in zephyr\dts\arm\st\wl\stm32wl.dtsi:392 */
				reg = < 0x0 >;                          /* in zephyr\dts\arm\st\wl\stm32wl.dtsi:393 */
				interrupts = < 0x32 0x0 >;              /* in zephyr\dts\arm\st\wl\stm32wl.dtsi:394 */
				spi-max-frequency = < 0x7a1200 >;       /* in zephyr\dts\arm\st\wl\stm32wl.dtsi:395 */
				status = "okay";                        /* in zephyr\boards\st\nucleo_wl55jc\nucleo_wl55jc.dts:187 */
				tx-enable-gpios = < &gpioc 0x4 0x1 >;   /* in zephyr\boards\st\nucleo_wl55jc\nucleo_wl55jc.dts:188 */
				rx-enable-gpios = < &gpioc 0x5 0x1 >;   /* in zephyr\boards\st\nucleo_wl55jc\nucleo_wl55jc.dts:189 */
				dio3-tcxo-voltage = < 0x1 >;            /* in zephyr\boards\st\nucleo_wl55jc\nucleo_wl55jc.dts:190 */
				tcxo-power-startup-delay-ms = < 0x5 >;  /* in zephyr\boards\st\nucleo_wl55jc\nucleo_wl55jc.dts:191 */
				power-amplifier-output = "rfo-hp";      /* in zephyr\boards\st\nucleo_wl55jc\nucleo_wl55jc.dts:197 */
				rfo-lp-max-power = < 0xf >;             /* in zephyr\boards\st\nucleo_wl55jc\nucleo_wl55jc.dts:198 */
				rfo-hp-max-power = < 0x16 >;            /* in zephyr\boards\st\nucleo_wl55jc\nucleo_wl55jc.dts:199 */
			};
		};

		/* node '/soc/adc@40012400' defined in zephyr\dts\arm\st\wl\stm32wl.dtsi:400 */
		adc1: adc@40012400 {
			compatible = "st,stm32-adc";                              /* in zephyr\dts\arm\st\wl\stm32wl.dtsi:401 */
			reg = < 0x40012400 0x400 >;                               /* in zephyr\dts\arm\st\wl\stm32wl.dtsi:402 */
			clocks = < &rcc 0x60 0x200 >;                             /* in zephyr\dts\arm\st\wl\stm32wl.dtsi:403 */
			clock-names = "adcx";                                     /* in zephyr\dts\arm\st\wl\stm32wl.dtsi:404 */
			interrupts = < 0x12 0x0 >;                                /* in zephyr\dts\arm\st\wl\stm32wl.dtsi:405 */
			#io-channel-cells = < 0x1 >;                              /* in zephyr\dts\arm\st\wl\stm32wl.dtsi:406 */
			st,adc-resolutions = < 0xc 0xa 0x8 0x6 >;                 /* in zephyr\dts\arm\st\wl\stm32wl.dtsi:407 */
			sampling-times = < 0x2 0x4 0x8 0xd 0x14 0x28 0x50 0xa1 >; /* in zephyr\dts\arm\st\wl\stm32wl.dtsi:408 */
			num-sampling-time-common-channels = < 0x2 >;              /* in zephyr\dts\arm\st\wl\stm32wl.dtsi:409 */
			st,adc-sequencer = "fixed";                               /* in zephyr\dts\arm\st\wl\stm32wl.dtsi:410 */
			st,adc-oversampler = "minimal";                           /* in zephyr\dts\arm\st\wl\stm32wl.dtsi:411 */
			st,adc-internal-regulator = "startup-sw-delay";           /* in zephyr\dts\arm\st\wl\stm32wl.dtsi:412 */
			pinctrl-0 = < &adc_in5_pb1 &adc_in0_pb13 >;               /* in zephyr\boards\st\nucleo_wl55jc\nucleo_wl55jc.dts:160 */
			pinctrl-names = "default";                                /* in zephyr\boards\st\nucleo_wl55jc\nucleo_wl55jc.dts:161 */
			st,adc-clock-source = "SYNC";                             /* in zephyr\boards\st\nucleo_wl55jc\nucleo_wl55jc.dts:162 */
			st,adc-prescaler = < 0x4 >;                               /* in zephyr\boards\st\nucleo_wl55jc\nucleo_wl55jc.dts:163 */
			status = "okay";                                          /* in zephyr\boards\st\nucleo_wl55jc\nucleo_wl55jc.dts:164 */
			phandle = < 0x1a >;                                       /* in zephyr\dts\arm\st\wl\stm32wl.dtsi:628 */
		};

		/* node '/soc/dac@40007400' defined in zephyr\dts\arm\st\wl\stm32wl.dtsi:416 */
		dac1: dac@40007400 {
			compatible = "st,stm32-dac";       /* in zephyr\dts\arm\st\wl\stm32wl.dtsi:417 */
			reg = < 0x40007400 0x400 >;        /* in zephyr\dts\arm\st\wl\stm32wl.dtsi:418 */
			clocks = < &rcc 0x58 0x20000000 >; /* in zephyr\dts\arm\st\wl\stm32wl.dtsi:419 */
			#io-channel-cells = < 0x1 >;       /* in zephyr\dts\arm\st\wl\stm32wl.dtsi:421 */
			pinctrl-0 = < &dac_out1_pa10 >;    /* in zephyr\boards\st\nucleo_wl55jc\nucleo_wl55jc.dts:144 */
			pinctrl-names = "default";         /* in zephyr\boards\st\nucleo_wl55jc\nucleo_wl55jc.dts:145 */
			status = "okay";                   /* in zephyr\boards\st\nucleo_wl55jc\nucleo_wl55jc.dts:146 */
		};

		/* node '/soc/timers@40012c00' defined in zephyr\dts\arm\st\wl\stm32wl.dtsi:424 */
		timers1: timers@40012c00 {
			compatible = "st,stm32-timers"; /* in zephyr\dts\arm\st\wl\stm32wl.dtsi:425 */
			reg = < 0x40012c00 0x400 >;     /* in zephyr\dts\arm\st\wl\stm32wl.dtsi:426 */
			clocks = < &rcc 0x60 0x800 >,
			         < &rcc 0x8 0xff >;     /* in zephyr\dts\arm\st\wl\stm32wl.dtsi:427 */
			resets = < &rctl 0x80b >;       /* in zephyr\dts\arm\st\wl\stm32wl.dtsi:429 */
			interrupts = < 0x17 0x0 >,
			             < 0x18 0x0 >,
			             < 0x19 0x0 >,
			             < 0x1a 0x0 >;      /* in zephyr\dts\arm\st\wl\stm32wl.dtsi:430 */
			interrupt-names = "brk",
			                  "up",
			                  "trgcom",
			                  "cc";         /* in zephyr\dts\arm\st\wl\stm32wl.dtsi:431 */
			st,prescaler = < 0x0 >;         /* in zephyr\dts\arm\st\wl\stm32wl.dtsi:432 */
			status = "disabled";            /* in zephyr\dts\arm\st\wl\stm32wl.dtsi:433 */

			/* node '/soc/timers@40012c00/pwm' defined in zephyr\dts\arm\st\wl\stm32wl.dtsi:435 */
			pwm {
				compatible = "st,stm32-pwm"; /* in zephyr\dts\arm\st\wl\stm32wl.dtsi:436 */
				status = "disabled";         /* in zephyr\dts\arm\st\wl\stm32wl.dtsi:437 */
				#pwm-cells = < 0x3 >;        /* in zephyr\dts\arm\st\wl\stm32wl.dtsi:438 */
			};

			/* node '/soc/timers@40012c00/counter' defined in zephyr\dts\arm\st\wl\stm32wl.dtsi:441 */
			counter {
				compatible = "st,stm32-counter"; /* in zephyr\dts\arm\st\wl\stm32wl.dtsi:442 */
				status = "disabled";             /* in zephyr\dts\arm\st\wl\stm32wl.dtsi:443 */
			};

			/* node '/soc/timers@40012c00/qdec' defined in zephyr\dts\arm\st\wl\stm32wl.dtsi:446 */
			qdec {
				compatible = "st,stm32-qdec";    /* in zephyr\dts\arm\st\wl\stm32wl.dtsi:447 */
				st,input-filter-level = < 0x0 >; /* in zephyr\dts\arm\st\wl\stm32wl.dtsi:448 */
				status = "disabled";             /* in zephyr\dts\arm\st\wl\stm32wl.dtsi:449 */
			};
		};

		/* node '/soc/timers@40000000' defined in zephyr\dts\arm\st\wl\stm32wl.dtsi:453 */
		timers2: timers@40000000 {
			compatible = "st,stm32-timers"; /* in zephyr\dts\arm\st\wl\stm32wl.dtsi:454 */
			reg = < 0x40000000 0x400 >;     /* in zephyr\dts\arm\st\wl\stm32wl.dtsi:455 */
			clocks = < &rcc 0x58 0x1 >,
			         < &rcc 0x7 0xff >;     /* in zephyr\dts\arm\st\wl\stm32wl.dtsi:456 */
			resets = < &rctl 0x700 >;       /* in zephyr\dts\arm\st\wl\stm32wl.dtsi:458 */
			interrupts = < 0x1b 0x0 >;      /* in zephyr\dts\arm\st\wl\stm32wl.dtsi:459 */
			interrupt-names = "global";     /* in zephyr\dts\arm\st\wl\stm32wl.dtsi:460 */
			st,prescaler = < 0x0 >;         /* in zephyr\dts\arm\st\wl\stm32wl.dtsi:461 */
			status = "okay";                /* in zephyr\boards\st\nucleo_wl55jc\nucleo_wl55jc.dts:150 */

			/* node '/soc/timers@40000000/pwm' defined in zephyr\dts\arm\st\wl\stm32wl.dtsi:464 */
			pwm2: pwm {
				compatible = "st,stm32-pwm";    /* in zephyr\dts\arm\st\wl\stm32wl.dtsi:465 */
				#pwm-cells = < 0x3 >;           /* in zephyr\dts\arm\st\wl\stm32wl.dtsi:467 */
				status = "okay";                /* in zephyr\boards\st\nucleo_wl55jc\nucleo_wl55jc.dts:153 */
				pinctrl-0 = < &tim2_ch4_pb11 >; /* in zephyr\boards\st\nucleo_wl55jc\nucleo_wl55jc.dts:154 */
				pinctrl-names = "default";      /* in zephyr\boards\st\nucleo_wl55jc\nucleo_wl55jc.dts:155 */
			};

			/* node '/soc/timers@40000000/counter' defined in zephyr\dts\arm\st\wl\stm32wl.dtsi:470 */
			counter {
				compatible = "st,stm32-counter"; /* in zephyr\dts\arm\st\wl\stm32wl.dtsi:471 */
				status = "disabled";             /* in zephyr\dts\arm\st\wl\stm32wl.dtsi:472 */
			};

			/* node '/soc/timers@40000000/qdec' defined in zephyr\dts\arm\st\wl\stm32wl.dtsi:475 */
			qdec {
				compatible = "st,stm32-qdec";    /* in zephyr\dts\arm\st\wl\stm32wl.dtsi:476 */
				st,input-filter-level = < 0x0 >; /* in zephyr\dts\arm\st\wl\stm32wl.dtsi:477 */
				status = "disabled";             /* in zephyr\dts\arm\st\wl\stm32wl.dtsi:478 */
			};
		};

		/* node '/soc/timers@40014400' defined in zephyr\dts\arm\st\wl\stm32wl.dtsi:482 */
		timers16: timers@40014400 {
			compatible = "st,stm32-timers"; /* in zephyr\dts\arm\st\wl\stm32wl.dtsi:483 */
			reg = < 0x40014400 0x400 >;     /* in zephyr\dts\arm\st\wl\stm32wl.dtsi:484 */
			clocks = < &rcc 0x60 0x20000 >,
			         < &rcc 0x8 0xff >;     /* in zephyr\dts\arm\st\wl\stm32wl.dtsi:485 */
			resets = < &rctl 0x811 >;       /* in zephyr\dts\arm\st\wl\stm32wl.dtsi:487 */
			interrupts = < 0x1c 0x0 >;      /* in zephyr\dts\arm\st\wl\stm32wl.dtsi:488 */
			interrupt-names = "global";     /* in zephyr\dts\arm\st\wl\stm32wl.dtsi:489 */
			st,prescaler = < 0x0 >;         /* in zephyr\dts\arm\st\wl\stm32wl.dtsi:490 */
			status = "disabled";            /* in zephyr\dts\arm\st\wl\stm32wl.dtsi:491 */

			/* node '/soc/timers@40014400/pwm' defined in zephyr\dts\arm\st\wl\stm32wl.dtsi:493 */
			pwm {
				compatible = "st,stm32-pwm"; /* in zephyr\dts\arm\st\wl\stm32wl.dtsi:494 */
				status = "disabled";         /* in zephyr\dts\arm\st\wl\stm32wl.dtsi:495 */
				#pwm-cells = < 0x3 >;        /* in zephyr\dts\arm\st\wl\stm32wl.dtsi:496 */
			};

			/* node '/soc/timers@40014400/counter' defined in zephyr\dts\arm\st\wl\stm32wl.dtsi:499 */
			counter {
				compatible = "st,stm32-counter"; /* in zephyr\dts\arm\st\wl\stm32wl.dtsi:500 */
				status = "disabled";             /* in zephyr\dts\arm\st\wl\stm32wl.dtsi:501 */
			};
		};

		/* node '/soc/timers@40014800' defined in zephyr\dts\arm\st\wl\stm32wl.dtsi:505 */
		timers17: timers@40014800 {
			compatible = "st,stm32-timers"; /* in zephyr\dts\arm\st\wl\stm32wl.dtsi:506 */
			reg = < 0x40014800 0x400 >;     /* in zephyr\dts\arm\st\wl\stm32wl.dtsi:507 */
			clocks = < &rcc 0x60 0x40000 >,
			         < &rcc 0x8 0xff >;     /* in zephyr\dts\arm\st\wl\stm32wl.dtsi:508 */
			resets = < &rctl 0x812 >;       /* in zephyr\dts\arm\st\wl\stm32wl.dtsi:510 */
			interrupts = < 0x1d 0x0 >;      /* in zephyr\dts\arm\st\wl\stm32wl.dtsi:511 */
			interrupt-names = "global";     /* in zephyr\dts\arm\st\wl\stm32wl.dtsi:512 */
			st,prescaler = < 0x0 >;         /* in zephyr\dts\arm\st\wl\stm32wl.dtsi:513 */
			status = "disabled";            /* in zephyr\dts\arm\st\wl\stm32wl.dtsi:514 */

			/* node '/soc/timers@40014800/pwm' defined in zephyr\dts\arm\st\wl\stm32wl.dtsi:516 */
			pwm {
				compatible = "st,stm32-pwm"; /* in zephyr\dts\arm\st\wl\stm32wl.dtsi:517 */
				status = "disabled";         /* in zephyr\dts\arm\st\wl\stm32wl.dtsi:518 */
				#pwm-cells = < 0x3 >;        /* in zephyr\dts\arm\st\wl\stm32wl.dtsi:519 */
			};

			/* node '/soc/timers@40014800/counter' defined in zephyr\dts\arm\st\wl\stm32wl.dtsi:522 */
			counter {
				compatible = "st,stm32-counter"; /* in zephyr\dts\arm\st\wl\stm32wl.dtsi:523 */
				status = "disabled";             /* in zephyr\dts\arm\st\wl\stm32wl.dtsi:524 */
			};
		};

		/* node '/soc/crypto@58001800' defined in zephyr\dts\arm\st\wl\stm32wl.dtsi:528 */
		aes: crypto@58001800 {
			compatible = "st,stm32-aes";    /* in zephyr\dts\arm\st\wl\stm32wl.dtsi:529 */
			reg = < 0x58001800 0x400 >;     /* in zephyr\dts\arm\st\wl\stm32wl.dtsi:530 */
			clocks = < &rcc 0x50 0x20000 >; /* in zephyr\dts\arm\st\wl\stm32wl.dtsi:531 */
			resets = < &rctl 0x610 >;       /* in zephyr\dts\arm\st\wl\stm32wl.dtsi:532 */
			interrupts = < 0x33 0x0 >;      /* in zephyr\dts\arm\st\wl\stm32wl.dtsi:533 */
			status = "okay";                /* in zephyr\boards\st\nucleo_wl55jc\nucleo_wl55jc.dts:172 */
		};

		/* node '/soc/rng@58001000' defined in zephyr\dts\arm\st\wl\stm32wl.dtsi:537 */
		rng: rng@58001000 {
			compatible = "st,stm32-rng";        /* in zephyr\dts\arm\st\wl\stm32wl.dtsi:538 */
			reg = < 0x58001000 0x400 >;         /* in zephyr\dts\arm\st\wl\stm32wl.dtsi:539 */
			interrupts = < 0x34 0x0 >;          /* in zephyr\dts\arm\st\wl\stm32wl.dtsi:540 */
			clocks = < &rcc 0x50 0x40000 >;     /* in zephyr\dts\arm\st\wl\stm32wl.dtsi:541 */
			nist-config = < 0xf00d00 >;         /* in zephyr\dts\arm\st\wl\stm32wl.dtsi:542 */
			health-test-magic = < 0x17590abc >; /* in zephyr\dts\arm\st\wl\stm32wl.dtsi:543 */
			health-test-config = < 0xaa74 >;    /* in zephyr\dts\arm\st\wl\stm32wl.dtsi:544 */
			status = "okay";                    /* in zephyr\boards\st\nucleo_wl55jc\nucleo_wl55jc.dts:176 */
		};

		/* node '/soc/dma@40020000' defined in zephyr\dts\arm\st\wl\stm32wl.dtsi:548 */
		dma1: dma@40020000 {
			compatible = "st,stm32-dma-v2"; /* in zephyr\dts\arm\st\wl\stm32wl.dtsi:549 */
			#dma-cells = < 0x3 >;           /* in zephyr\dts\arm\st\wl\stm32wl.dtsi:550 */
			reg = < 0x40020000 0x400 >;     /* in zephyr\dts\arm\st\wl\stm32wl.dtsi:551 */
			interrupts = < 0xb 0x0 >,
			             < 0xc 0x0 >,
			             < 0xd 0x0 >,
			             < 0xe 0x0 >,
			             < 0xf 0x0 >,
			             < 0x10 0x0 >,
			             < 0x11 0x0 >;      /* in zephyr\dts\arm\st\wl\stm32wl.dtsi:552 */
			clocks = < &rcc 0x48 0x1 >;     /* in zephyr\dts\arm\st\wl\stm32wl.dtsi:553 */
			dma-requests = < 0x7 >;         /* in zephyr\dts\arm\st\wl\stm32wl.dtsi:554 */
			dma-offset = < 0x0 >;           /* in zephyr\dts\arm\st\wl\stm32wl.dtsi:555 */
			status = "disabled";            /* in zephyr\dts\arm\st\wl\stm32wl.dtsi:556 */
		};

		/* node '/soc/dma@40020400' defined in zephyr\dts\arm\st\wl\stm32wl.dtsi:559 */
		dma2: dma@40020400 {
			compatible = "st,stm32-dma-v2"; /* in zephyr\dts\arm\st\wl\stm32wl.dtsi:560 */
			#dma-cells = < 0x3 >;           /* in zephyr\dts\arm\st\wl\stm32wl.dtsi:561 */
			reg = < 0x40020400 0x400 >;     /* in zephyr\dts\arm\st\wl\stm32wl.dtsi:562 */
			interrupts = < 0x36 0x0 >,
			             < 0x37 0x0 >,
			             < 0x38 0x0 >,
			             < 0x39 0x0 >,
			             < 0x3a 0x0 >,
			             < 0x3b 0x0 >,
			             < 0x3c 0x0 >;      /* in zephyr\dts\arm\st\wl\stm32wl.dtsi:563 */
			clocks = < &rcc 0x48 0x2 >;     /* in zephyr\dts\arm\st\wl\stm32wl.dtsi:564 */
			dma-requests = < 0x7 >;         /* in zephyr\dts\arm\st\wl\stm32wl.dtsi:565 */
			dma-offset = < 0x7 >;           /* in zephyr\dts\arm\st\wl\stm32wl.dtsi:566 */
			status = "disabled";            /* in zephyr\dts\arm\st\wl\stm32wl.dtsi:567 */
		};

		/* node '/soc/dmamux@40020800' defined in zephyr\dts\arm\st\wl\stm32wl.dtsi:570 */
		dmamux1: dmamux@40020800 {
			compatible = "st,stm32-dmamux"; /* in zephyr\dts\arm\st\wl\stm32wl.dtsi:571 */
			#dma-cells = < 0x3 >;           /* in zephyr\dts\arm\st\wl\stm32wl.dtsi:572 */
			reg = < 0x40020800 0x400 >;     /* in zephyr\dts\arm\st\wl\stm32wl.dtsi:573 */
			interrupts = < 0x3d 0x0 >;      /* in zephyr\dts\arm\st\wl\stm32wl.dtsi:574 */
			clocks = < &rcc 0x48 0x4 >;     /* in zephyr\dts\arm\st\wl\stm32wl.dtsi:575 */
			dma-channels = < 0xe >;         /* in zephyr\dts\arm\st\wl\stm32wl.dtsi:576 */
			dma-generators = < 0x4 >;       /* in zephyr\dts\arm\st\wl\stm32wl.dtsi:577 */
			dma-requests = < 0x26 >;        /* in zephyr\dts\arm\st\wl\stm32wl.dtsi:578 */
			status = "disabled";            /* in zephyr\dts\arm\st\wl\stm32wl.dtsi:579 */
		};

		/* node '/soc/power@58000400' defined in zephyr\dts\arm\st\wl\stm32wl.dtsi:582 */
		pwr: power@58000400 {
			compatible = "st,stm32-pwr"; /* in zephyr\dts\arm\st\wl\stm32wl.dtsi:583 */
			reg = < 0x58000400 0x400 >;  /* in zephyr\dts\arm\st\wl\stm32wl.dtsi:584 */

			/* node '/soc/power@58000400/wakeup-controller' defined in zephyr\dts\arm\st\wl\stm32wl.dtsi:586 */
			wakeup-controller {
				compatible = "st,stm32-pwr-wkupctrl"; /* in zephyr\dts\arm\st\wl\stm32wl.dtsi:587 */
				#address-cells = < 0x1 >;             /* in zephyr\dts\arm\st\wl\stm32wl.dtsi:588 */
				#size-cells = < 0x0 >;                /* in zephyr\dts\arm\st\wl\stm32wl.dtsi:589 */
				status = "disabled";                  /* in zephyr\dts\arm\st\wl\stm32wl.dtsi:590 */
				st,max-wkup-line-idx = < 0x3 >;       /* in zephyr\dts\arm\st\wl\stm32wl.dtsi:592 */
				st,has-pwr-full-pupd;                 /* in zephyr\dts\arm\st\wl\stm32wl.dtsi:593 */

				/* node '/soc/power@58000400/wakeup-controller/wkup@1' defined in zephyr\dts\arm\st\wl\stm32wl.dtsi:595 */
				wkup@1 {
					reg = < 0x1 >;                   /* in zephyr\dts\arm\st\wl\stm32wl.dtsi:596 */
					wkup-gpios = < &gpioa 0x0 0x0 >; /* in zephyr\dts\arm\st\wl\stm32wl.dtsi:597 */
				};

				/* node '/soc/power@58000400/wakeup-controller/wkup@2' defined in zephyr\dts\arm\st\wl\stm32wl.dtsi:600 */
				wkup@2 {
					reg = < 0x2 >;                   /* in zephyr\dts\arm\st\wl\stm32wl.dtsi:601 */
					wkup-gpios = < &gpioc 0xd 0x0 >; /* in zephyr\dts\arm\st\wl\stm32wl.dtsi:602 */
				};

				/* node '/soc/power@58000400/wakeup-controller/wkup@3' defined in zephyr\dts\arm\st\wl\stm32wl.dtsi:605 */
				wkup@3 {
					reg = < 0x3 >;                   /* in zephyr\dts\arm\st\wl\stm32wl.dtsi:606 */
					wkup-gpios = < &gpiob 0x3 0x0 >; /* in zephyr\dts\arm\st\wl\stm32wl.dtsi:607 */
				};
			};
		};

		/* node '/soc/crc@40023000' defined in zephyr\dts\arm\st\wl\stm32wl.dtsi:612 */
		crc: crc@40023000 {
			compatible = "st,stm32-crc";   /* in zephyr\dts\arm\st\wl\stm32wl.dtsi:613 */
			reg = < 0x40023000 0x400 >;    /* in zephyr\dts\arm\st\wl\stm32wl.dtsi:614 */
			clocks = < &rcc 0x48 0x1000 >; /* in zephyr\dts\arm\st\wl\stm32wl.dtsi:615 */
			resets = < &rctl 0x50c >;      /* in zephyr\dts\arm\st\wl\stm32wl.dtsi:616 */
			status = "okay";               /* in zephyr\boards\st\nucleo_wl55jc\nucleo_wl55jc.dts:251 */
		};
	};

	/* node '/cpus' defined in zephyr\dts\arm\st\wl\stm32wl.dtsi:29 */
	cpus {
		#address-cells = < 0x1 >; /* in zephyr\dts\arm\st\wl\stm32wl.dtsi:30 */
		#size-cells = < 0x0 >;    /* in zephyr\dts\arm\st\wl\stm32wl.dtsi:31 */

		/* node '/cpus/cpu@0' defined in zephyr\dts\arm\st\wl\stm32wl.dtsi:33 */
		cpu0: cpu@0 {
			device_type = "cpu";                         /* in zephyr\dts\arm\st\wl\stm32wl.dtsi:34 */
			compatible = "arm,cortex-m4";                /* in zephyr\dts\arm\st\wl\stm32wl.dtsi:35 */
			reg = < 0x0 >;                               /* in zephyr\dts\arm\st\wl\stm32wl.dtsi:36 */
			cpu-power-states = < &stop0 &stop1 &stop2 >; /* in zephyr\dts\arm\st\wl\stm32wl.dtsi:37 */
		};

		/* node '/cpus/power-states' defined in zephyr\dts\arm\st\wl\stm32wl.dtsi:40 */
		power-states {

			/* node '/cpus/power-states/state0' defined in zephyr\dts\arm\st\wl\stm32wl.dtsi:41 */
			stop0: state0 {
				compatible = "zephyr,power-state";    /* in zephyr\dts\arm\st\wl\stm32wl.dtsi:42 */
				power-state-name = "suspend-to-idle"; /* in zephyr\dts\arm\st\wl\stm32wl.dtsi:43 */
				substate-id = < 0x1 >;                /* in zephyr\dts\arm\st\wl\stm32wl.dtsi:44 */
				min-residency-us = < 0x64 >;          /* in zephyr\dts\arm\st\wl\stm32wl.dtsi:45 */
				phandle = < 0x14 >;                   /* in zephyr\dts\arm\st\wl\stm32wl.dtsi:37 */
			};

			/* node '/cpus/power-states/state1' defined in zephyr\dts\arm\st\wl\stm32wl.dtsi:48 */
			stop1: state1 {
				compatible = "zephyr,power-state";    /* in zephyr\dts\arm\st\wl\stm32wl.dtsi:49 */
				power-state-name = "suspend-to-idle"; /* in zephyr\dts\arm\st\wl\stm32wl.dtsi:50 */
				substate-id = < 0x2 >;                /* in zephyr\dts\arm\st\wl\stm32wl.dtsi:51 */
				min-residency-us = < 0x1f4 >;         /* in zephyr\dts\arm\st\wl\stm32wl.dtsi:52 */
				phandle = < 0x15 >;                   /* in zephyr\dts\arm\st\wl\stm32wl.dtsi:37 */
			};

			/* node '/cpus/power-states/state2' defined in zephyr\dts\arm\st\wl\stm32wl.dtsi:55 */
			stop2: state2 {
				compatible = "zephyr,power-state";    /* in zephyr\dts\arm\st\wl\stm32wl.dtsi:56 */
				power-state-name = "suspend-to-idle"; /* in zephyr\dts\arm\st\wl\stm32wl.dtsi:57 */
				substate-id = < 0x3 >;                /* in zephyr\dts\arm\st\wl\stm32wl.dtsi:58 */
				min-residency-us = < 0x384 >;         /* in zephyr\dts\arm\st\wl\stm32wl.dtsi:59 */
				phandle = < 0x16 >;                   /* in zephyr\dts\arm\st\wl\stm32wl.dtsi:37 */
			};
		};
	};

	/* node '/memory@20000000' defined in zephyr\dts\arm\st\wl\stm32wl.dtsi:64 */
	sram0: memory@20000000 {
		compatible = "zephyr,memory-region",
		             "mmio-sram";            /* in zephyr\dts\arm\st\wl\stm32wl.dtsi:65 */
		zephyr,memory-region = "SRAM0";      /* in zephyr\dts\arm\st\wl\stm32wl.dtsi:66 */
		reg = < 0x20000000 0x10000 >;        /* in zephyr\dts\arm\st\wl\stm32wl55Xc.dtsi:10 */
	};

	/* node '/clocks' defined in zephyr\dts\arm\st\wl\stm32wl.dtsi:69 */
	clocks {

		/* node '/clocks/clk-hse' defined in zephyr\dts\arm\st\wl\stm32wl.dtsi:70 */
		clk_hse: clk-hse {
			#clock-cells = < 0x0 >;              /* in zephyr\dts\arm\st\wl\stm32wl.dtsi:71 */
			compatible = "st,stm32wl-hse-clock"; /* in zephyr\dts\arm\st\wl\stm32wl.dtsi:72 */
			clock-frequency = < 0x1e84800 >;     /* in zephyr\dts\arm\st\wl\stm32wl.dtsi:74 */
			status = "disabled";                 /* in zephyr\dts\arm\st\wl\stm32wl.dtsi:75 */
		};

		/* node '/clocks/clk-hsi' defined in zephyr\dts\arm\st\wl\stm32wl.dtsi:78 */
		clk_hsi: clk-hsi {
			#clock-cells = < 0x0 >;         /* in zephyr\dts\arm\st\wl\stm32wl.dtsi:79 */
			compatible = "fixed-clock";     /* in zephyr\dts\arm\st\wl\stm32wl.dtsi:80 */
			clock-frequency = < 0xf42400 >; /* in zephyr\dts\arm\st\wl\stm32wl.dtsi:81 */
			status = "okay";                /* in zephyr\boards\st\nucleo_wl55jc\nucleo_wl55jc.dts:93 */
			phandle = < 0x17 >;             /* in zephyr\boards\st\nucleo_wl55jc\nucleo_wl55jc.dts:106 */
		};

		/* node '/clocks/clk-msi' defined in zephyr\dts\arm\st\wl\stm32wl.dtsi:85 */
		clk_msi: clk-msi {
			#clock-cells = < 0x0 >;            /* in zephyr\dts\arm\st\wl\stm32wl.dtsi:86 */
			compatible = "st,stm32-msi-clock"; /* in zephyr\dts\arm\st\wl\stm32wl.dtsi:87 */
			msi-range = < 0x6 >;               /* in zephyr\dts\arm\st\wl\stm32wl.dtsi:88 */
			status = "disabled";               /* in zephyr\dts\arm\st\wl\stm32wl.dtsi:89 */
		};

		/* node '/clocks/clk-lse' defined in zephyr\dts\arm\st\wl\stm32wl.dtsi:92 */
		clk_lse: clk-lse {
			#clock-cells = < 0x0 >;            /* in zephyr\dts\arm\st\wl\stm32wl.dtsi:93 */
			compatible = "st,stm32-lse-clock"; /* in zephyr\dts\arm\st\wl\stm32wl.dtsi:94 */
			clock-frequency = < 0x8000 >;      /* in zephyr\dts\arm\st\wl\stm32wl.dtsi:95 */
			driving-capability = < 0x0 >;      /* in zephyr\dts\arm\st\wl\stm32wl.dtsi:96 */
			status = "okay";                   /* in zephyr\boards\st\nucleo_wl55jc\nucleo_wl55jc.dts:97 */
		};

		/* node '/clocks/clk-lsi' defined in zephyr\dts\arm\st\wl\stm32wl.dtsi:100 */
		clk_lsi: clk-lsi {
			#clock-cells = < 0x0 >;       /* in zephyr\dts\arm\st\wl\stm32wl.dtsi:101 */
			compatible = "fixed-clock";   /* in zephyr\dts\arm\st\wl\stm32wl.dtsi:102 */
			clock-frequency = < 0x7d00 >; /* in zephyr\dts\arm\st\wl\stm32wl.dtsi:103 */
			status = "okay";              /* in zephyr\boards\st\nucleo_wl55jc\nucleo_wl55jc.dts:83 */
		};

		/* node '/clocks/pll' defined in zephyr\dts\arm\st\wl\stm32wl.dtsi:107 */
		pll: pll {
			#clock-cells = < 0x0 >;              /* in zephyr\dts\arm\st\wl\stm32wl.dtsi:108 */
			compatible = "st,stm32wb-pll-clock"; /* in zephyr\dts\arm\st\wl\stm32wl.dtsi:109 */
			div-m = < 0x1 >;                     /* in zephyr\boards\st\nucleo_wl55jc\nucleo_wl55jc.dts:101 */
			mul-n = < 0x6 >;                     /* in zephyr\boards\st\nucleo_wl55jc\nucleo_wl55jc.dts:102 */
			div-r = < 0x2 >;                     /* in zephyr\boards\st\nucleo_wl55jc\nucleo_wl55jc.dts:103 */
			div-q = < 0x2 >;                     /* in zephyr\boards\st\nucleo_wl55jc\nucleo_wl55jc.dts:104 */
			div-p = < 0x2 >;                     /* in zephyr\boards\st\nucleo_wl55jc\nucleo_wl55jc.dts:105 */
			clocks = < &clk_hsi >;               /* in zephyr\boards\st\nucleo_wl55jc\nucleo_wl55jc.dts:106 */
			status = "okay";                     /* in zephyr\boards\st\nucleo_wl55jc\nucleo_wl55jc.dts:107 */
			phandle = < 0x2 >;                   /* in zephyr\boards\st\nucleo_wl55jc\nucleo_wl55jc.dts:111 */
		};
	};

	/* node '/mcos' defined in zephyr\dts\arm\st\wl\stm32wl.dtsi:114 */
	mcos {

		/* node '/mcos/mco1' defined in zephyr\dts\arm\st\wl\stm32wl.dtsi:115 */
		mco1: mco1 {
			compatible = "st,stm32-clock-mco"; /* in zephyr\dts\arm\st\wl\stm32wl.dtsi:116 */
			clock-names = "clksel";            /* in zephyr\dts\arm\st\wl\stm32wl.dtsi:117 */
			status = "disabled";               /* in zephyr\dts\arm\st\wl\stm32wl.dtsi:118 */
		};
	};

	/* node '/dietemp' defined in zephyr\dts\arm\st\wl\stm32wl.dtsi:621 */
	die_temp: dietemp {
		compatible = "st,stm32-temp-cal"; /* in zephyr\dts\arm\st\wl\stm32wl.dtsi:622 */
		nvmem-cells = < &ts_cal1_otp >,
		              < &ts_cal2_otp >;   /* in zephyr\dts\arm\st\wl\stm32wl.dtsi:623 */
		nvmem-cell-names = "TS_CAL1",
		                   "TS_CAL2";     /* in zephyr\dts\arm\st\wl\stm32wl.dtsi:624 */
		ts-cal1-temp = < 0x1e >;          /* in zephyr\dts\arm\st\wl\stm32wl.dtsi:625 */
		ts-cal2-temp = < 0x82 >;          /* in zephyr\dts\arm\st\wl\stm32wl.dtsi:626 */
		ts-cal-vrefanalog = < 0xce4 >;    /* in zephyr\dts\arm\st\wl\stm32wl.dtsi:627 */
		io-channels = < &adc1 0xc >;      /* in zephyr\dts\arm\st\wl\stm32wl.dtsi:628 */
		status = "okay";                  /* in zephyr\boards\st\nucleo_wl55jc\nucleo_wl55jc.dts:168 */
	};

	/* node '/vref' defined in zephyr\dts\arm\st\wl\stm32wl.dtsi:632 */
	vref: vref {
		compatible = "st,stm32-vref";   /* in zephyr\dts\arm\st\wl\stm32wl.dtsi:633 */
		nvmem-cells = < &vrefint_otp >; /* in zephyr\dts\arm\st\wl\stm32wl.dtsi:634 */
		vrefint-cal-mv = < 0xce4 >;     /* in zephyr\dts\arm\st\wl\stm32wl.dtsi:635 */
		io-channels = < &adc1 0xd >;    /* in zephyr\dts\arm\st\wl\stm32wl.dtsi:636 */
		status = "okay";                /* in zephyr\boards\st\nucleo_wl55jc\nucleo_wl55jc.dts:243 */
	};

	/* node '/vbat' defined in zephyr\dts\arm\st\wl\stm32wl.dtsi:640 */
	vbat: vbat {
		compatible = "st,stm32-vbat"; /* in zephyr\dts\arm\st\wl\stm32wl.dtsi:641 */
		ratio = < 0x3 >;              /* in zephyr\dts\arm\st\wl\stm32wl.dtsi:642 */
		io-channels = < &adc1 0xe >;  /* in zephyr\dts\arm\st\wl\stm32wl.dtsi:643 */
		status = "okay";              /* in zephyr\boards\st\nucleo_wl55jc\nucleo_wl55jc.dts:247 */
	};

	/* node '/smbus1' defined in zephyr\dts\arm\st\wl\stm32wl.dtsi:647 */
	smbus1: smbus1 {
		compatible = "st,stm32-smbus"; /* in zephyr\dts\arm\st\wl\stm32wl.dtsi:648 */
		#address-cells = < 0x1 >;      /* in zephyr\dts\arm\st\wl\stm32wl.dtsi:649 */
		#size-cells = < 0x0 >;         /* in zephyr\dts\arm\st\wl\stm32wl.dtsi:650 */
		i2c = < &i2c1 >;               /* in zephyr\dts\arm\st\wl\stm32wl.dtsi:651 */
		status = "disabled";           /* in zephyr\dts\arm\st\wl\stm32wl.dtsi:652 */
	};

	/* node '/smbus2' defined in zephyr\dts\arm\st\wl\stm32wl.dtsi:655 */
	smbus2: smbus2 {
		compatible = "st,stm32-smbus"; /* in zephyr\dts\arm\st\wl\stm32wl.dtsi:656 */
		#address-cells = < 0x1 >;      /* in zephyr\dts\arm\st\wl\stm32wl.dtsi:657 */
		#size-cells = < 0x0 >;         /* in zephyr\dts\arm\st\wl\stm32wl.dtsi:658 */
		i2c = < &i2c2 >;               /* in zephyr\dts\arm\st\wl\stm32wl.dtsi:659 */
		status = "disabled";           /* in zephyr\dts\arm\st\wl\stm32wl.dtsi:660 */
	};

	/* node '/smbus3' defined in zephyr\dts\arm\st\wl\stm32wl.dtsi:663 */
	smbus3: smbus3 {
		compatible = "st,stm32-smbus"; /* in zephyr\dts\arm\st\wl\stm32wl.dtsi:664 */
		#address-cells = < 0x1 >;      /* in zephyr\dts\arm\st\wl\stm32wl.dtsi:665 */
		#size-cells = < 0x0 >;         /* in zephyr\dts\arm\st\wl\stm32wl.dtsi:666 */
		i2c = < &i2c3 >;               /* in zephyr\dts\arm\st\wl\stm32wl.dtsi:667 */
		status = "disabled";           /* in zephyr\dts\arm\st\wl\stm32wl.dtsi:668 */
	};

	/* node '/connector' defined in zephyr\boards\st\nucleo_wl55jc\arduino_r3_connector.dtsi:10 */
	arduino_header: connector {
		compatible = "arduino-header-r3";          /* in zephyr\boards\st\nucleo_wl55jc\arduino_r3_connector.dtsi:11 */
		#gpio-cells = < 0x2 >;                     /* in zephyr\boards\st\nucleo_wl55jc\arduino_r3_connector.dtsi:12 */
		gpio-map-mask = < 0xffffffff 0xffffffc0 >; /* in zephyr\boards\st\nucleo_wl55jc\arduino_r3_connector.dtsi:13 */
		gpio-map-pass-thru = < 0x0 0x3f >;         /* in zephyr\boards\st\nucleo_wl55jc\arduino_r3_connector.dtsi:14 */
		gpio-map = < 0x0 0x0 &gpiob 0x1 0x0 >,
		           < 0x1 0x0 &gpiob 0x2 0x0 >,
		           < 0x2 0x0 &gpioa 0xa 0x0 >,
		           < 0x3 0x0 &gpiob 0x4 0x0 >,
		           < 0x4 0x0 &gpiob 0xe 0x0 >,
		           < 0x5 0x0 &gpiob 0xd 0x0 >,
		           < 0x6 0x0 &gpiob 0x7 0x0 >,
		           < 0x7 0x0 &gpiob 0x6 0x0 >,
		           < 0x8 0x0 &gpiob 0xc 0x0 >,
		           < 0x9 0x0 &gpiob 0x3 0x0 >,
		           < 0xa 0x0 &gpiob 0x5 0x0 >,
		           < 0xb 0x0 &gpiob 0x8 0x0 >,
		           < 0xc 0x0 &gpiob 0xa 0x0 >,
		           < 0xd 0x0 &gpioc 0x1 0x0 >,
		           < 0xe 0x0 &gpioc 0x2 0x0 >,
		           < 0xf 0x0 &gpioa 0x9 0x0 >,
		           < 0x10 0x0 &gpioa 0x4 0x0 >,
		           < 0x11 0x0 &gpioa 0x7 0x0 >,
		           < 0x12 0x0 &gpioa 0x6 0x0 >,
		           < 0x13 0x0 &gpioa 0x5 0x0 >,
		           < 0x14 0x0 &gpioa 0xb 0x0 >,
		           < 0x15 0x0 &gpioa 0xc 0x0 >;    /* in zephyr\boards\st\nucleo_wl55jc\arduino_r3_connector.dtsi:15 */
	};

	/* node '/st-morpho-header' defined in zephyr\boards\st\nucleo_wl55jc\st_morpho_connector.dtsi:10 */
	st_morpho_header: st-morpho-header {
		compatible = "st-morpho-header";        /* in zephyr\boards\st\nucleo_wl55jc\st_morpho_connector.dtsi:11 */
		#gpio-cells = < 0x2 >;                  /* in zephyr\boards\st\nucleo_wl55jc\st_morpho_connector.dtsi:12 */
		gpio-map-mask = < 0xff 0x0 >;           /* in zephyr\boards\st\nucleo_wl55jc\st_morpho_connector.dtsi:13 */
		gpio-map-pass-thru = < 0x0 0x7f >;      /* in zephyr\boards\st\nucleo_wl55jc\st_morpho_connector.dtsi:14 */
		gpio-map = < 0x6 0x0 &gpioh 0x3 0x0 >,
		           < 0xc 0x0 &gpioa 0xd 0x0 >,
		           < 0xe 0x0 &gpioa 0xe 0x0 >,
		           < 0x10 0x0 &gpioa 0xf 0x0 >,
		           < 0x16 0x0 &gpioc 0xd 0x0 >,
		           < 0x18 0x0 &gpioc 0xe 0x0 >,
		           < 0x1a 0x0 &gpioc 0xf 0x0 >,
		           < 0x1b 0x0 &gpiob 0x1 0x0 >,
		           < 0x1d 0x0 &gpiob 0x2 0x0 >,
		           < 0x1f 0x0 &gpioa 0xa 0x0 >,
		           < 0x21 0x0 &gpiob 0x4 0x0 >,
		           < 0x23 0x0 &gpiob 0xe 0x0 >,
		           < 0x25 0x0 &gpiob 0xd 0x0 >,
		           < 0x48 0x0 &gpioa 0x0 0x0 >,
		           < 0x49 0x0 &gpioc 0x4 0x0 >,
		           < 0x4a 0x0 &gpioa 0xc 0x0 >,
		           < 0x4b 0x0 &gpioc 0x5 0x0 >,
		           < 0x4c 0x0 &gpioa 0xb 0x0 >,
		           < 0x52 0x0 &gpioa 0x5 0x0 >,
		           < 0x53 0x0 &gpioc 0x6 0x0 >,
		           < 0x54 0x0 &gpioa 0x6 0x0 >,
		           < 0x55 0x0 &gpioc 0x0 0x0 >,
		           < 0x56 0x0 &gpioa 0x7 0x0 >,
		           < 0x57 0x0 &gpioa 0x8 0x0 >,
		           < 0x58 0x0 &gpioa 0x4 0x0 >,
		           < 0x5a 0x0 &gpioa 0x9 0x0 >,
		           < 0x5c 0x0 &gpioc 0x2 0x0 >,
		           < 0x5d 0x0 &gpiob 0x0 0x0 >,
		           < 0x5e 0x0 &gpioc 0x1 0x0 >,
		           < 0x60 0x0 &gpiob 0xa 0x0 >,
		           < 0x61 0x0 &gpiob 0x9 0x0 >,
		           < 0x62 0x0 &gpiob 0x8 0x0 >,
		           < 0x63 0x0 &gpiob 0xf 0x0 >,
		           < 0x64 0x0 &gpiob 0x5 0x0 >,
		           < 0x65 0x0 &gpiob 0xb 0x0 >,
		           < 0x66 0x0 &gpiob 0x3 0x0 >,
		           < 0x68 0x0 &gpiob 0xc 0x0 >,
		           < 0x6a 0x0 &gpiob 0x6 0x0 >,
		           < 0x6b 0x0 &gpioa 0x1 0x0 >,
		           < 0x6c 0x0 &gpiob 0x7 0x0 >,
		           < 0x6d 0x0 &gpioc 0x3 0x0 >; /* in zephyr\boards\st\nucleo_wl55jc\st_morpho_connector.dtsi:15 */
	};

	/* node '/leds' defined in zephyr\boards\st\nucleo_wl55jc\nucleo_wl55jc.dts:27 */
	leds: leds {
		compatible = "gpio-leds"; /* in zephyr\boards\st\nucleo_wl55jc\nucleo_wl55jc.dts:28 */

		/* node '/leds/led_0' defined in zephyr\boards\st\nucleo_wl55jc\nucleo_wl55jc.dts:30 */
		blue_led_1: led_0 {
			gpios = < &gpiob 0xf 0x0 >; /* in zephyr\boards\st\nucleo_wl55jc\nucleo_wl55jc.dts:31 */
			label = "User LED1";        /* in zephyr\boards\st\nucleo_wl55jc\nucleo_wl55jc.dts:32 */
		};

		/* node '/leds/led_1' defined in zephyr\boards\st\nucleo_wl55jc\nucleo_wl55jc.dts:35 */
		green_led_2: led_1 {
			gpios = < &gpiob 0x9 0x0 >; /* in zephyr\boards\st\nucleo_wl55jc\nucleo_wl55jc.dts:36 */
			label = "User LED2";        /* in zephyr\boards\st\nucleo_wl55jc\nucleo_wl55jc.dts:37 */
		};

		/* node '/leds/led_2' defined in zephyr\boards\st\nucleo_wl55jc\nucleo_wl55jc.dts:40 */
		red_led_3: led_2 {
			gpios = < &gpiob 0xb 0x0 >; /* in zephyr\boards\st\nucleo_wl55jc\nucleo_wl55jc.dts:41 */
			label = "User LED3";        /* in zephyr\boards\st\nucleo_wl55jc\nucleo_wl55jc.dts:42 */
		};
	};

	/* node '/gpio_keys' defined in zephyr\boards\st\nucleo_wl55jc\nucleo_wl55jc.dts:46 */
	gpio_keys {
		compatible = "gpio-keys"; /* in zephyr\boards\st\nucleo_wl55jc\nucleo_wl55jc.dts:47 */

		/* node '/gpio_keys/button_0' defined in zephyr\boards\st\nucleo_wl55jc\nucleo_wl55jc.dts:49 */
		user_button_1: button_0 {
			label = "SW1";               /* in zephyr\boards\st\nucleo_wl55jc\nucleo_wl55jc.dts:50 */
			gpios = < &gpioa 0x0 0x11 >; /* in zephyr\boards\st\nucleo_wl55jc\nucleo_wl55jc.dts:51 */
			zephyr,code = < 0xb >;       /* in zephyr\boards\st\nucleo_wl55jc\nucleo_wl55jc.dts:52 */
		};

		/* node '/gpio_keys/button_1' defined in zephyr\boards\st\nucleo_wl55jc\nucleo_wl55jc.dts:55 */
		user_button_2: button_1 {
			label = "SW2";               /* in zephyr\boards\st\nucleo_wl55jc\nucleo_wl55jc.dts:56 */
			gpios = < &gpioa 0x1 0x11 >; /* in zephyr\boards\st\nucleo_wl55jc\nucleo_wl55jc.dts:57 */
			zephyr,code = < 0x2 >;       /* in zephyr\boards\st\nucleo_wl55jc\nucleo_wl55jc.dts:58 */
		};

		/* node '/gpio_keys/button_2' defined in zephyr\boards\st\nucleo_wl55jc\nucleo_wl55jc.dts:61 */
		user_button_3: button_2 {
			label = "SW3";               /* in zephyr\boards\st\nucleo_wl55jc\nucleo_wl55jc.dts:62 */
			gpios = < &gpioc 0x6 0x11 >; /* in zephyr\boards\st\nucleo_wl55jc\nucleo_wl55jc.dts:63 */
			zephyr,code = < 0x3 >;       /* in zephyr\boards\st\nucleo_wl55jc\nucleo_wl55jc.dts:64 */
		};
	};
};
